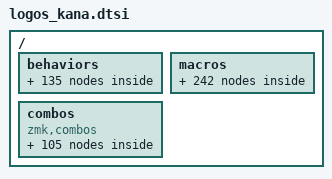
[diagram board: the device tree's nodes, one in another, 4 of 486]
// Generated by tools/generate_logos_kana_zmk.py. Do not edit manually.

#ifndef LOGOS_KANA_LAYER
#error "LOGOS_KANA_LAYER must be defined before including logos_kana.dtsi"
#endif
#ifndef LOGOS_KANA_TOTAL_POSITIONS
#error "LOGOS_KANA_TOTAL_POSITIONS must be defined before including logos_kana.dtsi"
#endif
#ifndef LOGOS_KANA_ROW_LENGTHS
#error "LOGOS_KANA_ROW_LENGTHS must be defined before including logos_kana.dtsi"
#endif
#ifndef LOGOS_KANA_TOGGLE_POSITION
#error "LOGOS_KANA_TOGGLE_POSITION must be defined before including logos_kana.dtsi"
#endif
#ifndef LOGOS_KANA_LAYER_BINDINGS
#error "LOGOS_KANA_LAYER_BINDINGS must be defined before including logos_kana.dtsi"
#endif
#ifndef LOGOS_KANA_POS_Q
#error "LOGOS_KANA_POS_Q must be defined before including logos_kana.dtsi"
#endif
#ifndef LOGOS_KANA_POS_W
#error "LOGOS_KANA_POS_W must be defined before including logos_kana.dtsi"
#endif
#ifndef LOGOS_KANA_POS_E
#error "LOGOS_KANA_POS_E must be defined before including logos_kana.dtsi"
#endif
#ifndef LOGOS_KANA_POS_R
#error "LOGOS_KANA_POS_R must be defined before including logos_kana.dtsi"
#endif
#ifndef LOGOS_KANA_POS_T
#error "LOGOS_KANA_POS_T must be defined before including logos_kana.dtsi"
#endif
#ifndef LOGOS_KANA_POS_Y
#error "LOGOS_KANA_POS_Y must be defined before including logos_kana.dtsi"
#endif
#ifndef LOGOS_KANA_POS_U
#error "LOGOS_KANA_POS_U must be defined before including logos_kana.dtsi"
#endif
#ifndef LOGOS_KANA_POS_I
#error "LOGOS_KANA_POS_I must be defined before including logos_kana.dtsi"
#endif
#ifndef LOGOS_KANA_POS_O
#error "LOGOS_KANA_POS_O must be defined before including logos_kana.dtsi"
#endif
#ifndef LOGOS_KANA_POS_P
#error "LOGOS_KANA_POS_P must be defined before including logos_kana.dtsi"
#endif
#ifndef LOGOS_KANA_POS_A
#error "LOGOS_KANA_POS_A must be defined before including logos_kana.dtsi"
#endif
#ifndef LOGOS_KANA_POS_S
#error "LOGOS_KANA_POS_S must be defined before including logos_kana.dtsi"
#endif
#ifndef LOGOS_KANA_POS_D
#error "LOGOS_KANA_POS_D must be defined before including logos_kana.dtsi"
#endif
#ifndef LOGOS_KANA_POS_F
#error "LOGOS_KANA_POS_F must be defined before including logos_kana.dtsi"
#endif
#ifndef LOGOS_KANA_POS_G
#error "LOGOS_KANA_POS_G must be defined before including logos_kana.dtsi"
#endif
#ifndef LOGOS_KANA_POS_H
#error "LOGOS_KANA_POS_H must be defined before including logos_kana.dtsi"
#endif
#ifndef LOGOS_KANA_POS_J
#error "LOGOS_KANA_POS_J must be defined before including logos_kana.dtsi"
#endif
#ifndef LOGOS_KANA_POS_K
#error "LOGOS_KANA_POS_K must be defined before including logos_kana.dtsi"
#endif
#ifndef LOGOS_KANA_POS_L
#error "LOGOS_KANA_POS_L must be defined before including logos_kana.dtsi"
#endif
#ifndef LOGOS_KANA_POS_SEMI
#error "LOGOS_KANA_POS_SEMI must be defined before including logos_kana.dtsi"
#endif
#ifndef LOGOS_KANA_POS_Z
#error "LOGOS_KANA_POS_Z must be defined before including logos_kana.dtsi"
#endif
#ifndef LOGOS_KANA_POS_X
#error "LOGOS_KANA_POS_X must be defined before including logos_kana.dtsi"
#endif
#ifndef LOGOS_KANA_POS_C
#error "LOGOS_KANA_POS_C must be defined before including logos_kana.dtsi"
#endif
#ifndef LOGOS_KANA_POS_V
#error "LOGOS_KANA_POS_V must be defined before including logos_kana.dtsi"
#endif
#ifndef LOGOS_KANA_POS_B
#error "LOGOS_KANA_POS_B must be defined before including logos_kana.dtsi"
#endif
#ifndef LOGOS_KANA_POS_N
#error "LOGOS_KANA_POS_N must be defined before including logos_kana.dtsi"
#endif
#ifndef LOGOS_KANA_POS_M
#error "LOGOS_KANA_POS_M must be defined before including logos_kana.dtsi"
#endif
#ifndef LOGOS_KANA_POS_COMMA
#error "LOGOS_KANA_POS_COMMA must be defined before including logos_kana.dtsi"
#endif
#ifndef LOGOS_KANA_POS_DOT
#error "LOGOS_KANA_POS_DOT must be defined before including logos_kana.dtsi"
#endif
#ifndef LOGOS_KANA_POS_SLASH
#error "LOGOS_KANA_POS_SLASH must be defined before including logos_kana.dtsi"
#endif
#ifndef LOGOS_KANA_FALLBACK_Q
#error "LOGOS_KANA_FALLBACK_Q must be defined before including logos_kana.dtsi"
#endif
#ifndef LOGOS_KANA_FALLBACK_W
#error "LOGOS_KANA_FALLBACK_W must be defined before including logos_kana.dtsi"
#endif
#ifndef LOGOS_KANA_FALLBACK_E
#error "LOGOS_KANA_FALLBACK_E must be defined before including logos_kana.dtsi"
#endif
#ifndef LOGOS_KANA_FALLBACK_R
#error "LOGOS_KANA_FALLBACK_R must be defined before including logos_kana.dtsi"
#endif
#ifndef LOGOS_KANA_FALLBACK_T
#error "LOGOS_KANA_FALLBACK_T must be defined before including logos_kana.dtsi"
#endif
#ifndef LOGOS_KANA_FALLBACK_Y
#error "LOGOS_KANA_FALLBACK_Y must be defined before including logos_kana.dtsi"
#endif
#ifndef LOGOS_KANA_FALLBACK_U
#error "LOGOS_KANA_FALLBACK_U must be defined before including logos_kana.dtsi"
#endif
#ifndef LOGOS_KANA_FALLBACK_I
#error "LOGOS_KANA_FALLBACK_I must be defined before including logos_kana.dtsi"
#endif
#ifndef LOGOS_KANA_FALLBACK_O
#error "LOGOS_KANA_FALLBACK_O must be defined before including logos_kana.dtsi"
#endif
#ifndef LOGOS_KANA_FALLBACK_P
#error "LOGOS_KANA_FALLBACK_P must be defined before including logos_kana.dtsi"
#endif
#ifndef LOGOS_KANA_FALLBACK_A
#error "LOGOS_KANA_FALLBACK_A must be defined before including logos_kana.dtsi"
#endif
#ifndef LOGOS_KANA_FALLBACK_S
#error "LOGOS_KANA_FALLBACK_S must be defined before including logos_kana.dtsi"
#endif
#ifndef LOGOS_KANA_FALLBACK_D
#error "LOGOS_KANA_FALLBACK_D must be defined before including logos_kana.dtsi"
#endif
#ifndef LOGOS_KANA_FALLBACK_F
#error "LOGOS_KANA_FALLBACK_F must be defined before including logos_kana.dtsi"
#endif
#ifndef LOGOS_KANA_FALLBACK_G
#error "LOGOS_KANA_FALLBACK_G must be defined before including logos_kana.dtsi"
#endif
#ifndef LOGOS_KANA_FALLBACK_H
#error "LOGOS_KANA_FALLBACK_H must be defined before including logos_kana.dtsi"
#endif
#ifndef LOGOS_KANA_FALLBACK_J
#error "LOGOS_KANA_FALLBACK_J must be defined before including logos_kana.dtsi"
#endif
#ifndef LOGOS_KANA_FALLBACK_K
#error "LOGOS_KANA_FALLBACK_K must be defined before including logos_kana.dtsi"
#endif
#ifndef LOGOS_KANA_FALLBACK_L
#error "LOGOS_KANA_FALLBACK_L must be defined before including logos_kana.dtsi"
#endif
#ifndef LOGOS_KANA_FALLBACK_SEMI
#error "LOGOS_KANA_FALLBACK_SEMI must be defined before including logos_kana.dtsi"
#endif
#ifndef LOGOS_KANA_FALLBACK_Z
#error "LOGOS_KANA_FALLBACK_Z must be defined before including logos_kana.dtsi"
#endif
#ifndef LOGOS_KANA_FALLBACK_X
#error "LOGOS_KANA_FALLBACK_X must be defined before including logos_kana.dtsi"
#endif
#ifndef LOGOS_KANA_FALLBACK_C
#error "LOGOS_KANA_FALLBACK_C must be defined before including logos_kana.dtsi"
#endif
#ifndef LOGOS_KANA_FALLBACK_V
#error "LOGOS_KANA_FALLBACK_V must be defined before including logos_kana.dtsi"
#endif
#ifndef LOGOS_KANA_FALLBACK_B
#error "LOGOS_KANA_FALLBACK_B must be defined before including logos_kana.dtsi"
#endif
#ifndef LOGOS_KANA_FALLBACK_N
#error "LOGOS_KANA_FALLBACK_N must be defined before including logos_kana.dtsi"
#endif
#ifndef LOGOS_KANA_FALLBACK_M
#error "LOGOS_KANA_FALLBACK_M must be defined before including logos_kana.dtsi"
#endif
#ifndef LOGOS_KANA_FALLBACK_COMMA
#error "LOGOS_KANA_FALLBACK_COMMA must be defined before including logos_kana.dtsi"
#endif
#ifndef LOGOS_KANA_FALLBACK_DOT
#error "LOGOS_KANA_FALLBACK_DOT must be defined before including logos_kana.dtsi"
#endif
#ifndef LOGOS_KANA_FALLBACK_SLASH
#error "LOGOS_KANA_FALLBACK_SLASH must be defined before including logos_kana.dtsi"
#endif

#ifndef LOGOS_KANA_COMBO_TIMEOUT_MS
#define LOGOS_KANA_COMBO_TIMEOUT_MS 60
#endif

#ifndef LOGOS_KANA_MACRO_WAIT_MS
#define LOGOS_KANA_MACRO_WAIT_MS 40
#endif

#ifndef LOGOS_KANA_MACRO_TAP_MS
#define LOGOS_KANA_MACRO_TAP_MS 40
#endif

#ifndef LOGOS_KANA_MODS
#define LOGOS_KANA_MODS (MOD_LCTL|MOD_RCTL|MOD_LSFT|MOD_RSFT|MOD_LALT|MOD_RALT|MOD_LGUI|MOD_RGUI)
#endif

#ifndef LOGOS_KANA_ON_BINDINGS
#define LOGOS_KANA_ON_BINDINGS <&tog LOGOS_KANA_LAYER>
#endif

#ifndef LOGOS_KANA_OFF_BINDINGS
#define LOGOS_KANA_OFF_BINDINGS <&tog LOGOS_KANA_LAYER>
#endif

#define LOGOS_KANA_LAYER_NODE \
        logos_kana_layer { \
            display-name = "Logos Kana"; \
            bindings = < \
LOGOS_KANA_LAYER_BINDINGS \
            >; \
        };

/ {
    behaviors {
        logos_kana_se_key: logos_kana_se_key {
            compatible = "zmk,behavior-mod-morph";
            #binding-cells = <0>;
            bindings = <&logos_kana_se>, <&kp LOGOS_KANA_FALLBACK_Q>;
            mods = <LOGOS_KANA_MODS>;
            keep-mods = <LOGOS_KANA_MODS>;
        };

        logos_kana_sa_key: logos_kana_sa_key {
            compatible = "zmk,behavior-mod-morph";
            #binding-cells = <0>;
            bindings = <&logos_kana_sa>, <&kp LOGOS_KANA_FALLBACK_W>;
            mods = <LOGOS_KANA_MODS>;
            keep-mods = <LOGOS_KANA_MODS>;
        };

        logos_kana_ha_key: logos_kana_ha_key {
            compatible = "zmk,behavior-mod-morph";
            #binding-cells = <0>;
            bindings = <&logos_kana_ha>, <&kp LOGOS_KANA_FALLBACK_E>;
            mods = <LOGOS_KANA_MODS>;
            keep-mods = <LOGOS_KANA_MODS>;
        };

        logos_kana_te_key: logos_kana_te_key {
            compatible = "zmk,behavior-mod-morph";
            #binding-cells = <0>;
            bindings = <&logos_kana_te>, <&kp LOGOS_KANA_FALLBACK_R>;
            mods = <LOGOS_KANA_MODS>;
            keep-mods = <LOGOS_KANA_MODS>;
        };

        logos_kana_wo_key: logos_kana_wo_key {
            compatible = "zmk,behavior-mod-morph";
            #binding-cells = <0>;
            bindings = <&logos_kana_wo>, <&kp LOGOS_KANA_FALLBACK_T>;
            mods = <LOGOS_KANA_MODS>;
            keep-mods = <LOGOS_KANA_MODS>;
        };

        logos_kana_ti_key: logos_kana_ti_key {
            compatible = "zmk,behavior-mod-morph";
            #binding-cells = <0>;
            bindings = <&logos_kana_ti>, <&kp LOGOS_KANA_FALLBACK_Y>;
            mods = <LOGOS_KANA_MODS>;
            keep-mods = <LOGOS_KANA_MODS>;
        };

        logos_kana_tu_key: logos_kana_tu_key {
            compatible = "zmk,behavior-mod-morph";
            #binding-cells = <0>;
            bindings = <&logos_kana_tu>, <&kp LOGOS_KANA_FALLBACK_U>;
            mods = <LOGOS_KANA_MODS>;
            keep-mods = <LOGOS_KANA_MODS>;
        };

        logos_kana_ku_key: logos_kana_ku_key {
            compatible = "zmk,behavior-mod-morph";
            #binding-cells = <0>;
            bindings = <&logos_kana_ku>, <&kp LOGOS_KANA_FALLBACK_I>;
            mods = <LOGOS_KANA_MODS>;
            keep-mods = <LOGOS_KANA_MODS>;
        };

        logos_kana_xtu_key: logos_kana_xtu_key {
            compatible = "zmk,behavior-mod-morph";
            #binding-cells = <0>;
            bindings = <&logos_kana_xtu>, <&kp LOGOS_KANA_FALLBACK_O>;
            mods = <LOGOS_KANA_MODS>;
            keep-mods = <LOGOS_KANA_MODS>;
        };

        logos_kana_hi_key: logos_kana_hi_key {
            compatible = "zmk,behavior-mod-morph";
            #binding-cells = <0>;
            bindings = <&logos_kana_hi>, <&kp LOGOS_KANA_FALLBACK_P>;
            mods = <LOGOS_KANA_MODS>;
            keep-mods = <LOGOS_KANA_MODS>;
        };

        logos_kana_ka_key: logos_kana_ka_key {
            compatible = "zmk,behavior-mod-morph";
            #binding-cells = <0>;
            bindings = <&logos_kana_ka>, <&kp LOGOS_KANA_FALLBACK_A>;
            mods = <LOGOS_KANA_MODS>;
            keep-mods = <LOGOS_KANA_MODS>;
        };

        logos_kana_to_key: logos_kana_to_key {
            compatible = "zmk,behavior-mod-morph";
            #binding-cells = <0>;
            bindings = <&logos_kana_to>, <&kp LOGOS_KANA_FALLBACK_S>;
            mods = <LOGOS_KANA_MODS>;
            keep-mods = <LOGOS_KANA_MODS>;
        };

        logos_kana_ta_key: logos_kana_ta_key {
            compatible = "zmk,behavior-mod-morph";
            #binding-cells = <0>;
            bindings = <&logos_kana_ta>, <&kp LOGOS_KANA_FALLBACK_D>;
            mods = <LOGOS_KANA_MODS>;
            keep-mods = <LOGOS_KANA_MODS>;
        };

        logos_kana_no_key: logos_kana_no_key {
            compatible = "zmk,behavior-mod-morph";
            #binding-cells = <0>;
            bindings = <&logos_kana_no>, <&kp LOGOS_KANA_FALLBACK_F>;
            mods = <LOGOS_KANA_MODS>;
            keep-mods = <LOGOS_KANA_MODS>;
        };

        logos_kana_ni_key: logos_kana_ni_key {
            compatible = "zmk,behavior-mod-morph";
            #binding-cells = <0>;
            bindings = <&logos_kana_ni>, <&kp LOGOS_KANA_FALLBACK_G>;
            mods = <LOGOS_KANA_MODS>;
            keep-mods = <LOGOS_KANA_MODS>;
        };

        logos_kana_comma_key: logos_kana_comma_key {
            compatible = "zmk,behavior-mod-morph";
            #binding-cells = <0>;
            bindings = <&logos_kana_comma>, <&kp LOGOS_KANA_FALLBACK_H>;
            mods = <LOGOS_KANA_MODS>;
            keep-mods = <LOGOS_KANA_MODS>;
        };

        logos_kana_nn_key: logos_kana_nn_key {
            compatible = "zmk,behavior-mod-morph";
            #binding-cells = <0>;
            bindings = <&logos_kana_nn>, <&kp LOGOS_KANA_FALLBACK_J>;
            mods = <LOGOS_KANA_MODS>;
            keep-mods = <LOGOS_KANA_MODS>;
        };

        logos_kana_i_key: logos_kana_i_key {
            compatible = "zmk,behavior-mod-morph";
            #binding-cells = <0>;
            bindings = <&logos_kana_i>, <&kp LOGOS_KANA_FALLBACK_K>;
            mods = <LOGOS_KANA_MODS>;
            keep-mods = <LOGOS_KANA_MODS>;
        };

        logos_kana_u_key: logos_kana_u_key {
            compatible = "zmk,behavior-mod-morph";
            #binding-cells = <0>;
            bindings = <&logos_kana_u>, <&kp LOGOS_KANA_FALLBACK_L>;
            mods = <LOGOS_KANA_MODS>;
            keep-mods = <LOGOS_KANA_MODS>;
        };

        logos_kana_si_key: logos_kana_si_key {
            compatible = "zmk,behavior-mod-morph";
            #binding-cells = <0>;
            bindings = <&logos_kana_si>, <&kp LOGOS_KANA_FALLBACK_SEMI>;
            mods = <LOGOS_KANA_MODS>;
            keep-mods = <LOGOS_KANA_MODS>;
        };

        logos_kana_yo_key: logos_kana_yo_key {
            compatible = "zmk,behavior-mod-morph";
            #binding-cells = <0>;
            bindings = <&logos_kana_yo>, <&kp LOGOS_KANA_FALLBACK_Z>;
            mods = <LOGOS_KANA_MODS>;
            keep-mods = <LOGOS_KANA_MODS>;
        };

        logos_kana_da_key: logos_kana_da_key {
            compatible = "zmk,behavior-mod-morph";
            #binding-cells = <0>;
            bindings = <&logos_kana_da>, <&kp LOGOS_KANA_FALLBACK_X>;
            mods = <LOGOS_KANA_MODS>;
            keep-mods = <LOGOS_KANA_MODS>;
        };

        logos_kana_do_key: logos_kana_do_key {
            compatible = "zmk,behavior-mod-morph";
            #binding-cells = <0>;
            bindings = <&logos_kana_do>, <&kp LOGOS_KANA_FALLBACK_C>;
            mods = <LOGOS_KANA_MODS>;
            keep-mods = <LOGOS_KANA_MODS>;
        };

        logos_kana_ga_key: logos_kana_ga_key {
            compatible = "zmk,behavior-mod-morph";
            #binding-cells = <0>;
            bindings = <&logos_kana_ga>, <&kp LOGOS_KANA_FALLBACK_V>;
            mods = <LOGOS_KANA_MODS>;
            keep-mods = <LOGOS_KANA_MODS>;
        };

        logos_kana_ra_key: logos_kana_ra_key {
            compatible = "zmk,behavior-mod-morph";
            #binding-cells = <0>;
            bindings = <&logos_kana_ra>, <&kp LOGOS_KANA_FALLBACK_B>;
            mods = <LOGOS_KANA_MODS>;
            keep-mods = <LOGOS_KANA_MODS>;
        };

        logos_kana_wa_key: logos_kana_wa_key {
            compatible = "zmk,behavior-mod-morph";
            #binding-cells = <0>;
            bindings = <&logos_kana_wa>, <&kp LOGOS_KANA_FALLBACK_N>;
            mods = <LOGOS_KANA_MODS>;
            keep-mods = <LOGOS_KANA_MODS>;
        };

        logos_kana_ru_key: logos_kana_ru_key {
            compatible = "zmk,behavior-mod-morph";
            #binding-cells = <0>;
            bindings = <&logos_kana_ru>, <&kp LOGOS_KANA_FALLBACK_M>;
            mods = <LOGOS_KANA_MODS>;
            keep-mods = <LOGOS_KANA_MODS>;
        };

        logos_kana_long_key: logos_kana_long_key {
            compatible = "zmk,behavior-mod-morph";
            #binding-cells = <0>;
            bindings = <&logos_kana_long>, <&kp LOGOS_KANA_FALLBACK_COMMA>;
            mods = <LOGOS_KANA_MODS>;
            keep-mods = <LOGOS_KANA_MODS>;
        };

        logos_kana_re_key: logos_kana_re_key {
            compatible = "zmk,behavior-mod-morph";
            #binding-cells = <0>;
            bindings = <&logos_kana_re>, <&kp LOGOS_KANA_FALLBACK_DOT>;
            mods = <LOGOS_KANA_MODS>;
            keep-mods = <LOGOS_KANA_MODS>;
        };

        logos_kana_e_key: logos_kana_e_key {
            compatible = "zmk,behavior-mod-morph";
            #binding-cells = <0>;
            bindings = <&logos_kana_e>, <&kp LOGOS_KANA_FALLBACK_SLASH>;
            mods = <LOGOS_KANA_MODS>;
            keep-mods = <LOGOS_KANA_MODS>;
        };

        logos_kana_di_combo: logos_kana_di_combo {
            compatible = "zmk,behavior-mod-morph";
            #binding-cells = <0>;
            bindings = <&logos_kana_di>, <&logos_kana_di_pass>;
            mods = <LOGOS_KANA_MODS>;
            keep-mods = <LOGOS_KANA_MODS>;
        };

        logos_kana_ge_combo: logos_kana_ge_combo {
            compatible = "zmk,behavior-mod-morph";
            #binding-cells = <0>;
            bindings = <&logos_kana_ge>, <&logos_kana_ge_pass>;
            mods = <LOGOS_KANA_MODS>;
            keep-mods = <LOGOS_KANA_MODS>;
        };

        logos_kana_ho_combo: logos_kana_ho_combo {
            compatible = "zmk,behavior-mod-morph";
            #binding-cells = <0>;
            bindings = <&logos_kana_ho>, <&logos_kana_ho_pass>;
            mods = <LOGOS_KANA_MODS>;
            keep-mods = <LOGOS_KANA_MODS>;
        };

        logos_kana_gi_combo: logos_kana_gi_combo {
            compatible = "zmk,behavior-mod-morph";
            #binding-cells = <0>;
            bindings = <&logos_kana_gi>, <&logos_kana_gi_pass>;
            mods = <LOGOS_KANA_MODS>;
            keep-mods = <LOGOS_KANA_MODS>;
        };

        logos_kana_ze_combo: logos_kana_ze_combo {
            compatible = "zmk,behavior-mod-morph";
            #binding-cells = <0>;
            bindings = <&logos_kana_ze>, <&logos_kana_ze_pass>;
            mods = <LOGOS_KANA_MODS>;
            keep-mods = <LOGOS_KANA_MODS>;
        };

        logos_kana_du_combo: logos_kana_du_combo {
            compatible = "zmk,behavior-mod-morph";
            #binding-cells = <0>;
            bindings = <&logos_kana_du>, <&logos_kana_du_pass>;
            mods = <LOGOS_KANA_MODS>;
            keep-mods = <LOGOS_KANA_MODS>;
        };

        logos_kana_yu_combo: logos_kana_yu_combo {
            compatible = "zmk,behavior-mod-morph";
            #binding-cells = <0>;
            bindings = <&logos_kana_yu>, <&logos_kana_yu_pass>;
            mods = <LOGOS_KANA_MODS>;
            keep-mods = <LOGOS_KANA_MODS>;
        };

        logos_kana_hu_combo: logos_kana_hu_combo {
            compatible = "zmk,behavior-mod-morph";
            #binding-cells = <0>;
            bindings = <&logos_kana_hu>, <&logos_kana_hu_pass>;
            mods = <LOGOS_KANA_MODS>;
            keep-mods = <LOGOS_KANA_MODS>;
        };

        logos_kana_bi_combo: logos_kana_bi_combo {
            compatible = "zmk,behavior-mod-morph";
            #binding-cells = <0>;
            bindings = <&logos_kana_bi>, <&logos_kana_bi_pass>;
            mods = <LOGOS_KANA_MODS>;
            keep-mods = <LOGOS_KANA_MODS>;
        };

        logos_kana_vu_combo: logos_kana_vu_combo {
            compatible = "zmk,behavior-mod-morph";
            #binding-cells = <0>;
            bindings = <&logos_kana_vu>, <&logos_kana_vu_pass>;
            mods = <LOGOS_KANA_MODS>;
            keep-mods = <LOGOS_KANA_MODS>;
        };

        logos_kana_ke_combo: logos_kana_ke_combo {
            compatible = "zmk,behavior-mod-morph";
            #binding-cells = <0>;
            bindings = <&logos_kana_ke>, <&logos_kana_ke_pass>;
            mods = <LOGOS_KANA_MODS>;
            keep-mods = <LOGOS_KANA_MODS>;
        };

        logos_kana_na_combo: logos_kana_na_combo {
            compatible = "zmk,behavior-mod-morph";
            #binding-cells = <0>;
            bindings = <&logos_kana_na>, <&logos_kana_na_pass>;
            mods = <LOGOS_KANA_MODS>;
            keep-mods = <LOGOS_KANA_MODS>;
        };

        logos_kana_ko_combo: logos_kana_ko_combo {
            compatible = "zmk,behavior-mod-morph";
            #binding-cells = <0>;
            bindings = <&logos_kana_ko>, <&logos_kana_ko_pass>;
            mods = <LOGOS_KANA_MODS>;
            keep-mods = <LOGOS_KANA_MODS>;
        };

        logos_kana_period_combo: logos_kana_period_combo {
            compatible = "zmk,behavior-mod-morph";
            #binding-cells = <0>;
            bindings = <&logos_kana_period>, <&logos_kana_period_pass>;
            mods = <LOGOS_KANA_MODS>;
            keep-mods = <LOGOS_KANA_MODS>;
        };

        logos_kana_zi_combo: logos_kana_zi_combo {
            compatible = "zmk,behavior-mod-morph";
            #binding-cells = <0>;
            bindings = <&logos_kana_zi>, <&logos_kana_zi_pass>;
            mods = <LOGOS_KANA_MODS>;
            keep-mods = <LOGOS_KANA_MODS>;
        };

        logos_kana_so_combo: logos_kana_so_combo {
            compatible = "zmk,behavior-mod-morph";
            #binding-cells = <0>;
            bindings = <&logos_kana_so>, <&logos_kana_so_pass>;
            mods = <LOGOS_KANA_MODS>;
            keep-mods = <LOGOS_KANA_MODS>;
        };

        logos_kana_o_combo: logos_kana_o_combo {
            compatible = "zmk,behavior-mod-morph";
            #binding-cells = <0>;
            bindings = <&logos_kana_o>, <&logos_kana_o_pass>;
            mods = <LOGOS_KANA_MODS>;
            keep-mods = <LOGOS_KANA_MODS>;
        };

        logos_kana_a_combo: logos_kana_a_combo {
            compatible = "zmk,behavior-mod-morph";
            #binding-cells = <0>;
            bindings = <&logos_kana_a>, <&logos_kana_a_pass>;
            mods = <LOGOS_KANA_MODS>;
            keep-mods = <LOGOS_KANA_MODS>;
        };

        logos_kana_pi_combo: logos_kana_pi_combo {
            compatible = "zmk,behavior-mod-morph";
            #binding-cells = <0>;
            bindings = <&logos_kana_pi>, <&logos_kana_pi_pass>;
            mods = <LOGOS_KANA_MODS>;
            keep-mods = <LOGOS_KANA_MODS>;
        };

        logos_kana_po_combo: logos_kana_po_combo {
            compatible = "zmk,behavior-mod-morph";
            #binding-cells = <0>;
            bindings = <&logos_kana_po>, <&logos_kana_po_pass>;
            mods = <LOGOS_KANA_MODS>;
            keep-mods = <LOGOS_KANA_MODS>;
        };

        logos_kana_ne_combo: logos_kana_ne_combo {
            compatible = "zmk,behavior-mod-morph";
            #binding-cells = <0>;
            bindings = <&logos_kana_ne>, <&logos_kana_ne_pass>;
            mods = <LOGOS_KANA_MODS>;
            keep-mods = <LOGOS_KANA_MODS>;
        };

        logos_kana_ba_combo: logos_kana_ba_combo {
            compatible = "zmk,behavior-mod-morph";
            #binding-cells = <0>;
            bindings = <&logos_kana_ba>, <&logos_kana_ba_pass>;
            mods = <LOGOS_KANA_MODS>;
            keep-mods = <LOGOS_KANA_MODS>;
        };

        logos_kana_pa_combo: logos_kana_pa_combo {
            compatible = "zmk,behavior-mod-morph";
            #binding-cells = <0>;
            bindings = <&logos_kana_pa>, <&logos_kana_pa_pass>;
            mods = <LOGOS_KANA_MODS>;
            keep-mods = <LOGOS_KANA_MODS>;
        };

        logos_kana_nu_combo: logos_kana_nu_combo {
            compatible = "zmk,behavior-mod-morph";
            #binding-cells = <0>;
            bindings = <&logos_kana_nu>, <&logos_kana_nu_pass>;
            mods = <LOGOS_KANA_MODS>;
            keep-mods = <LOGOS_KANA_MODS>;
        };

        logos_kana_mi_combo: logos_kana_mi_combo {
            compatible = "zmk,behavior-mod-morph";
            #binding-cells = <0>;
            bindings = <&logos_kana_mi>, <&logos_kana_mi_pass>;
            mods = <LOGOS_KANA_MODS>;
            keep-mods = <LOGOS_KANA_MODS>;
        };

        logos_kana_gu_combo: logos_kana_gu_combo {
            compatible = "zmk,behavior-mod-morph";
            #binding-cells = <0>;
            bindings = <&logos_kana_gu>, <&logos_kana_gu_pass>;
            mods = <LOGOS_KANA_MODS>;
            keep-mods = <LOGOS_KANA_MODS>;
        };

        logos_kana_dhi_combo: logos_kana_dhi_combo {
            compatible = "zmk,behavior-mod-morph";
            #binding-cells = <0>;
            bindings = <&logos_kana_dhi>, <&logos_kana_dhi_pass>;
            mods = <LOGOS_KANA_MODS>;
            keep-mods = <LOGOS_KANA_MODS>;
        };

        logos_kana_pu_combo: logos_kana_pu_combo {
            compatible = "zmk,behavior-mod-morph";
            #binding-cells = <0>;
            bindings = <&logos_kana_pu>, <&logos_kana_pu_pass>;
            mods = <LOGOS_KANA_MODS>;
            keep-mods = <LOGOS_KANA_MODS>;
        };

        logos_kana_xa_combo: logos_kana_xa_combo {
            compatible = "zmk,behavior-mod-morph";
            #binding-cells = <0>;
            bindings = <&logos_kana_xa>, <&logos_kana_xa_pass>;
            mods = <LOGOS_KANA_MODS>;
            keep-mods = <LOGOS_KANA_MODS>;
        };

        logos_kana_me_combo: logos_kana_me_combo {
            compatible = "zmk,behavior-mod-morph";
            #binding-cells = <0>;
            bindings = <&logos_kana_me>, <&logos_kana_me_pass>;
            mods = <LOGOS_KANA_MODS>;
            keep-mods = <LOGOS_KANA_MODS>;
        };

        logos_kana_bu_combo: logos_kana_bu_combo {
            compatible = "zmk,behavior-mod-morph";
            #binding-cells = <0>;
            bindings = <&logos_kana_bu>, <&logos_kana_bu_pass>;
            mods = <LOGOS_KANA_MODS>;
            keep-mods = <LOGOS_KANA_MODS>;
        };

        logos_kana_za_combo: logos_kana_za_combo {
            compatible = "zmk,behavior-mod-morph";
            #binding-cells = <0>;
            bindings = <&logos_kana_za>, <&logos_kana_za_pass>;
            mods = <LOGOS_KANA_MODS>;
            keep-mods = <LOGOS_KANA_MODS>;
        };

        logos_kana_xi_combo: logos_kana_xi_combo {
            compatible = "zmk,behavior-mod-morph";
            #binding-cells = <0>;
            bindings = <&logos_kana_xi>, <&logos_kana_xi_pass>;
            mods = <LOGOS_KANA_MODS>;
            keep-mods = <LOGOS_KANA_MODS>;
        };

        logos_kana_xu_combo: logos_kana_xu_combo {
            compatible = "zmk,behavior-mod-morph";
            #binding-cells = <0>;
            bindings = <&logos_kana_xu>, <&logos_kana_xu_pass>;
            mods = <LOGOS_KANA_MODS>;
            keep-mods = <LOGOS_KANA_MODS>;
        };

        logos_kana_zo_combo: logos_kana_zo_combo {
            compatible = "zmk,behavior-mod-morph";
            #binding-cells = <0>;
            bindings = <&logos_kana_zo>, <&logos_kana_zo_pass>;
            mods = <LOGOS_KANA_MODS>;
            keep-mods = <LOGOS_KANA_MODS>;
        };

        logos_kana_go_combo: logos_kana_go_combo {
            compatible = "zmk,behavior-mod-morph";
            #binding-cells = <0>;
            bindings = <&logos_kana_go>, <&logos_kana_go_pass>;
            mods = <LOGOS_KANA_MODS>;
            keep-mods = <LOGOS_KANA_MODS>;
        };

        logos_kana_be_combo: logos_kana_be_combo {
            compatible = "zmk,behavior-mod-morph";
            #binding-cells = <0>;
            bindings = <&logos_kana_be>, <&logos_kana_be_pass>;
            mods = <LOGOS_KANA_MODS>;
            keep-mods = <LOGOS_KANA_MODS>;
        };

        logos_kana_xe_combo: logos_kana_xe_combo {
            compatible = "zmk,behavior-mod-morph";
            #binding-cells = <0>;
            bindings = <&logos_kana_xe>, <&logos_kana_xe_pass>;
            mods = <LOGOS_KANA_MODS>;
            keep-mods = <LOGOS_KANA_MODS>;
        };

        logos_kana_ki_combo: logos_kana_ki_combo {
            compatible = "zmk,behavior-mod-morph";
            #binding-cells = <0>;
            bindings = <&logos_kana_ki>, <&logos_kana_ki_pass>;
            mods = <LOGOS_KANA_MODS>;
            keep-mods = <LOGOS_KANA_MODS>;
        };

        logos_kana_ri_combo: logos_kana_ri_combo {
            compatible = "zmk,behavior-mod-morph";
            #binding-cells = <0>;
            bindings = <&logos_kana_ri>, <&logos_kana_ri_pass>;
            mods = <LOGOS_KANA_MODS>;
            keep-mods = <LOGOS_KANA_MODS>;
        };

        logos_kana_su_combo: logos_kana_su_combo {
            compatible = "zmk,behavior-mod-morph";
            #binding-cells = <0>;
            bindings = <&logos_kana_su>, <&logos_kana_su_pass>;
            mods = <LOGOS_KANA_MODS>;
            keep-mods = <LOGOS_KANA_MODS>;
        };

        logos_kana_de_combo: logos_kana_de_combo {
            compatible = "zmk,behavior-mod-morph";
            #binding-cells = <0>;
            bindings = <&logos_kana_de>, <&logos_kana_de_pass>;
            mods = <LOGOS_KANA_MODS>;
            keep-mods = <LOGOS_KANA_MODS>;
        };

        logos_kana_ya_combo: logos_kana_ya_combo {
            compatible = "zmk,behavior-mod-morph";
            #binding-cells = <0>;
            bindings = <&logos_kana_ya>, <&logos_kana_ya_pass>;
            mods = <LOGOS_KANA_MODS>;
            keep-mods = <LOGOS_KANA_MODS>;
        };

        logos_kana_ro_combo: logos_kana_ro_combo {
            compatible = "zmk,behavior-mod-morph";
            #binding-cells = <0>;
            bindings = <&logos_kana_ro>, <&logos_kana_ro_pass>;
            mods = <LOGOS_KANA_MODS>;
            keep-mods = <LOGOS_KANA_MODS>;
        };

        logos_kana_ma_combo: logos_kana_ma_combo {
            compatible = "zmk,behavior-mod-morph";
            #binding-cells = <0>;
            bindings = <&logos_kana_ma>, <&logos_kana_ma_pass>;
            mods = <LOGOS_KANA_MODS>;
            keep-mods = <LOGOS_KANA_MODS>;
        };

        logos_kana_mo_combo: logos_kana_mo_combo {
            compatible = "zmk,behavior-mod-morph";
            #binding-cells = <0>;
            bindings = <&logos_kana_mo>, <&logos_kana_mo_pass>;
            mods = <LOGOS_KANA_MODS>;
            keep-mods = <LOGOS_KANA_MODS>;
        };

        logos_kana_xo_combo: logos_kana_xo_combo {
            compatible = "zmk,behavior-mod-morph";
            #binding-cells = <0>;
            bindings = <&logos_kana_xo>, <&logos_kana_xo_pass>;
            mods = <LOGOS_KANA_MODS>;
            keep-mods = <LOGOS_KANA_MODS>;
        };

        logos_kana_pe_combo: logos_kana_pe_combo {
            compatible = "zmk,behavior-mod-morph";
            #binding-cells = <0>;
            bindings = <&logos_kana_pe>, <&logos_kana_pe_pass>;
            mods = <LOGOS_KANA_MODS>;
            keep-mods = <LOGOS_KANA_MODS>;
        };

        logos_kana_bo_combo: logos_kana_bo_combo {
            compatible = "zmk,behavior-mod-morph";
            #binding-cells = <0>;
            bindings = <&logos_kana_bo>, <&logos_kana_bo_pass>;
            mods = <LOGOS_KANA_MODS>;
            keep-mods = <LOGOS_KANA_MODS>;
        };

        logos_kana_he_combo: logos_kana_he_combo {
            compatible = "zmk,behavior-mod-morph";
            #binding-cells = <0>;
            bindings = <&logos_kana_he>, <&logos_kana_he_pass>;
            mods = <LOGOS_KANA_MODS>;
            keep-mods = <LOGOS_KANA_MODS>;
        };

        logos_kana_xya_combo: logos_kana_xya_combo {
            compatible = "zmk,behavior-mod-morph";
            #binding-cells = <0>;
            bindings = <&logos_kana_xya>, <&logos_kana_xya_pass>;
            mods = <LOGOS_KANA_MODS>;
            keep-mods = <LOGOS_KANA_MODS>;
        };

        logos_kana_xyu_combo: logos_kana_xyu_combo {
            compatible = "zmk,behavior-mod-morph";
            #binding-cells = <0>;
            bindings = <&logos_kana_xyu>, <&logos_kana_xyu_pass>;
            mods = <LOGOS_KANA_MODS>;
            keep-mods = <LOGOS_KANA_MODS>;
        };

        logos_kana_mu_combo: logos_kana_mu_combo {
            compatible = "zmk,behavior-mod-morph";
            #binding-cells = <0>;
            bindings = <&logos_kana_mu>, <&logos_kana_mu_pass>;
            mods = <LOGOS_KANA_MODS>;
            keep-mods = <LOGOS_KANA_MODS>;
        };

        logos_kana_zu_combo: logos_kana_zu_combo {
            compatible = "zmk,behavior-mod-morph";
            #binding-cells = <0>;
            bindings = <&logos_kana_zu>, <&logos_kana_zu_pass>;
            mods = <LOGOS_KANA_MODS>;
            keep-mods = <LOGOS_KANA_MODS>;
        };

        logos_kana_thi_combo: logos_kana_thi_combo {
            compatible = "zmk,behavior-mod-morph";
            #binding-cells = <0>;
            bindings = <&logos_kana_thi>, <&logos_kana_thi_pass>;
            mods = <LOGOS_KANA_MODS>;
            keep-mods = <LOGOS_KANA_MODS>;
        };

        logos_kana_xyo_combo: logos_kana_xyo_combo {
            compatible = "zmk,behavior-mod-morph";
            #binding-cells = <0>;
            bindings = <&logos_kana_xyo>, <&logos_kana_xyo_pass>;
            mods = <LOGOS_KANA_MODS>;
            keep-mods = <LOGOS_KANA_MODS>;
        };

        logos_kana_sya_combo: logos_kana_sya_combo {
            compatible = "zmk,behavior-mod-morph";
            #binding-cells = <0>;
            bindings = <&logos_kana_sya>, <&logos_kana_sya_pass>;
            mods = <LOGOS_KANA_MODS>;
            keep-mods = <LOGOS_KANA_MODS>;
        };

        logos_kana_syu_combo: logos_kana_syu_combo {
            compatible = "zmk,behavior-mod-morph";
            #binding-cells = <0>;
            bindings = <&logos_kana_syu>, <&logos_kana_syu_pass>;
            mods = <LOGOS_KANA_MODS>;
            keep-mods = <LOGOS_KANA_MODS>;
        };

        logos_kana_syo_combo: logos_kana_syo_combo {
            compatible = "zmk,behavior-mod-morph";
            #binding-cells = <0>;
            bindings = <&logos_kana_syo>, <&logos_kana_syo_pass>;
            mods = <LOGOS_KANA_MODS>;
            keep-mods = <LOGOS_KANA_MODS>;
        };

        logos_kana_kya_combo: logos_kana_kya_combo {
            compatible = "zmk,behavior-mod-morph";
            #binding-cells = <0>;
            bindings = <&logos_kana_kya>, <&logos_kana_kya_pass>;
            mods = <LOGOS_KANA_MODS>;
            keep-mods = <LOGOS_KANA_MODS>;
        };

        logos_kana_kyu_combo: logos_kana_kyu_combo {
            compatible = "zmk,behavior-mod-morph";
            #binding-cells = <0>;
            bindings = <&logos_kana_kyu>, <&logos_kana_kyu_pass>;
            mods = <LOGOS_KANA_MODS>;
            keep-mods = <LOGOS_KANA_MODS>;
        };

        logos_kana_kyo_combo: logos_kana_kyo_combo {
            compatible = "zmk,behavior-mod-morph";
            #binding-cells = <0>;
            bindings = <&logos_kana_kyo>, <&logos_kana_kyo_pass>;
            mods = <LOGOS_KANA_MODS>;
            keep-mods = <LOGOS_KANA_MODS>;
        };

        logos_kana_tya_combo: logos_kana_tya_combo {
            compatible = "zmk,behavior-mod-morph";
            #binding-cells = <0>;
            bindings = <&logos_kana_tya>, <&logos_kana_tya_pass>;
            mods = <LOGOS_KANA_MODS>;
            keep-mods = <LOGOS_KANA_MODS>;
        };

        logos_kana_tyu_combo: logos_kana_tyu_combo {
            compatible = "zmk,behavior-mod-morph";
            #binding-cells = <0>;
            bindings = <&logos_kana_tyu>, <&logos_kana_tyu_pass>;
            mods = <LOGOS_KANA_MODS>;
            keep-mods = <LOGOS_KANA_MODS>;
        };

        logos_kana_tyo_combo: logos_kana_tyo_combo {
            compatible = "zmk,behavior-mod-morph";
            #binding-cells = <0>;
            bindings = <&logos_kana_tyo>, <&logos_kana_tyo_pass>;
            mods = <LOGOS_KANA_MODS>;
            keep-mods = <LOGOS_KANA_MODS>;
        };

        logos_kana_hya_combo: logos_kana_hya_combo {
            compatible = "zmk,behavior-mod-morph";
            #binding-cells = <0>;
            bindings = <&logos_kana_hya>, <&logos_kana_hya_pass>;
            mods = <LOGOS_KANA_MODS>;
            keep-mods = <LOGOS_KANA_MODS>;
        };

        logos_kana_hyu_combo: logos_kana_hyu_combo {
            compatible = "zmk,behavior-mod-morph";
            #binding-cells = <0>;
            bindings = <&logos_kana_hyu>, <&logos_kana_hyu_pass>;
            mods = <LOGOS_KANA_MODS>;
            keep-mods = <LOGOS_KANA_MODS>;
        };

        logos_kana_hyo_combo: logos_kana_hyo_combo {
            compatible = "zmk,behavior-mod-morph";
            #binding-cells = <0>;
            bindings = <&logos_kana_hyo>, <&logos_kana_hyo_pass>;
            mods = <LOGOS_KANA_MODS>;
            keep-mods = <LOGOS_KANA_MODS>;
        };

        logos_kana_ja_combo: logos_kana_ja_combo {
            compatible = "zmk,behavior-mod-morph";
            #binding-cells = <0>;
            bindings = <&logos_kana_ja>, <&logos_kana_ja_pass>;
            mods = <LOGOS_KANA_MODS>;
            keep-mods = <LOGOS_KANA_MODS>;
        };

        logos_kana_ju_combo: logos_kana_ju_combo {
            compatible = "zmk,behavior-mod-morph";
            #binding-cells = <0>;
            bindings = <&logos_kana_ju>, <&logos_kana_ju_pass>;
            mods = <LOGOS_KANA_MODS>;
            keep-mods = <LOGOS_KANA_MODS>;
        };

        logos_kana_jo_combo: logos_kana_jo_combo {
            compatible = "zmk,behavior-mod-morph";
            #binding-cells = <0>;
            bindings = <&logos_kana_jo>, <&logos_kana_jo_pass>;
            mods = <LOGOS_KANA_MODS>;
            keep-mods = <LOGOS_KANA_MODS>;
        };

        logos_kana_gya_combo: logos_kana_gya_combo {
            compatible = "zmk,behavior-mod-morph";
            #binding-cells = <0>;
            bindings = <&logos_kana_gya>, <&logos_kana_gya_pass>;
            mods = <LOGOS_KANA_MODS>;
            keep-mods = <LOGOS_KANA_MODS>;
        };

        logos_kana_gyu_combo: logos_kana_gyu_combo {
            compatible = "zmk,behavior-mod-morph";
            #binding-cells = <0>;
            bindings = <&logos_kana_gyu>, <&logos_kana_gyu_pass>;
            mods = <LOGOS_KANA_MODS>;
            keep-mods = <LOGOS_KANA_MODS>;
        };

        logos_kana_gyo_combo: logos_kana_gyo_combo {
            compatible = "zmk,behavior-mod-morph";
            #binding-cells = <0>;
            bindings = <&logos_kana_gyo>, <&logos_kana_gyo_pass>;
            mods = <LOGOS_KANA_MODS>;
            keep-mods = <LOGOS_KANA_MODS>;
        };

        logos_kana_nya_combo: logos_kana_nya_combo {
            compatible = "zmk,behavior-mod-morph";
            #binding-cells = <0>;
            bindings = <&logos_kana_nya>, <&logos_kana_nya_pass>;
            mods = <LOGOS_KANA_MODS>;
            keep-mods = <LOGOS_KANA_MODS>;
        };

        logos_kana_nyu_combo: logos_kana_nyu_combo {
            compatible = "zmk,behavior-mod-morph";
            #binding-cells = <0>;
            bindings = <&logos_kana_nyu>, <&logos_kana_nyu_pass>;
            mods = <LOGOS_KANA_MODS>;
            keep-mods = <LOGOS_KANA_MODS>;
        };

        logos_kana_nyo_combo: logos_kana_nyo_combo {
            compatible = "zmk,behavior-mod-morph";
            #binding-cells = <0>;
            bindings = <&logos_kana_nyo>, <&logos_kana_nyo_pass>;
            mods = <LOGOS_KANA_MODS>;
            keep-mods = <LOGOS_KANA_MODS>;
        };

        logos_kana_bya_combo: logos_kana_bya_combo {
            compatible = "zmk,behavior-mod-morph";
            #binding-cells = <0>;
            bindings = <&logos_kana_bya>, <&logos_kana_bya_pass>;
            mods = <LOGOS_KANA_MODS>;
            keep-mods = <LOGOS_KANA_MODS>;
        };

        logos_kana_byu_combo: logos_kana_byu_combo {
            compatible = "zmk,behavior-mod-morph";
            #binding-cells = <0>;
            bindings = <&logos_kana_byu>, <&logos_kana_byu_pass>;
            mods = <LOGOS_KANA_MODS>;
            keep-mods = <LOGOS_KANA_MODS>;
        };

        logos_kana_byo_combo: logos_kana_byo_combo {
            compatible = "zmk,behavior-mod-morph";
            #binding-cells = <0>;
            bindings = <&logos_kana_byo>, <&logos_kana_byo_pass>;
            mods = <LOGOS_KANA_MODS>;
            keep-mods = <LOGOS_KANA_MODS>;
        };

        logos_kana_rya_combo: logos_kana_rya_combo {
            compatible = "zmk,behavior-mod-morph";
            #binding-cells = <0>;
            bindings = <&logos_kana_rya>, <&logos_kana_rya_pass>;
            mods = <LOGOS_KANA_MODS>;
            keep-mods = <LOGOS_KANA_MODS>;
        };

        logos_kana_ryu_combo: logos_kana_ryu_combo {
            compatible = "zmk,behavior-mod-morph";
            #binding-cells = <0>;
            bindings = <&logos_kana_ryu>, <&logos_kana_ryu_pass>;
            mods = <LOGOS_KANA_MODS>;
            keep-mods = <LOGOS_KANA_MODS>;
        };

        logos_kana_ryo_combo: logos_kana_ryo_combo {
            compatible = "zmk,behavior-mod-morph";
            #binding-cells = <0>;
            bindings = <&logos_kana_ryo>, <&logos_kana_ryo_pass>;
            mods = <LOGOS_KANA_MODS>;
            keep-mods = <LOGOS_KANA_MODS>;
        };

        logos_kana_mya_combo: logos_kana_mya_combo {
            compatible = "zmk,behavior-mod-morph";
            #binding-cells = <0>;
            bindings = <&logos_kana_mya>, <&logos_kana_mya_pass>;
            mods = <LOGOS_KANA_MODS>;
            keep-mods = <LOGOS_KANA_MODS>;
        };

        logos_kana_myu_combo: logos_kana_myu_combo {
            compatible = "zmk,behavior-mod-morph";
            #binding-cells = <0>;
            bindings = <&logos_kana_myu>, <&logos_kana_myu_pass>;
            mods = <LOGOS_KANA_MODS>;
            keep-mods = <LOGOS_KANA_MODS>;
        };

        logos_kana_myo_combo: logos_kana_myo_combo {
            compatible = "zmk,behavior-mod-morph";
            #binding-cells = <0>;
            bindings = <&logos_kana_myo>, <&logos_kana_myo_pass>;
            mods = <LOGOS_KANA_MODS>;
            keep-mods = <LOGOS_KANA_MODS>;
        };

        logos_kana_vi_combo: logos_kana_vi_combo {
            compatible = "zmk,behavior-mod-morph";
            #binding-cells = <0>;
            bindings = <&logos_kana_vi>, <&logos_kana_vi_pass>;
            mods = <LOGOS_KANA_MODS>;
            keep-mods = <LOGOS_KANA_MODS>;
        };

        logos_kana_va_combo: logos_kana_va_combo {
            compatible = "zmk,behavior-mod-morph";
            #binding-cells = <0>;
            bindings = <&logos_kana_va>, <&logos_kana_va_pass>;
            mods = <LOGOS_KANA_MODS>;
            keep-mods = <LOGOS_KANA_MODS>;
        };

        logos_kana_che_combo: logos_kana_che_combo {
            compatible = "zmk,behavior-mod-morph";
            #binding-cells = <0>;
            bindings = <&logos_kana_che>, <&logos_kana_che_pass>;
            mods = <LOGOS_KANA_MODS>;
            keep-mods = <LOGOS_KANA_MODS>;
        };

        logos_kana_pya_combo: logos_kana_pya_combo {
            compatible = "zmk,behavior-mod-morph";
            #binding-cells = <0>;
            bindings = <&logos_kana_pya>, <&logos_kana_pya_pass>;
            mods = <LOGOS_KANA_MODS>;
            keep-mods = <LOGOS_KANA_MODS>;
        };

        logos_kana_pyu_combo: logos_kana_pyu_combo {
            compatible = "zmk,behavior-mod-morph";
            #binding-cells = <0>;
            bindings = <&logos_kana_pyu>, <&logos_kana_pyu_pass>;
            mods = <LOGOS_KANA_MODS>;
            keep-mods = <LOGOS_KANA_MODS>;
        };

        logos_kana_pyo_combo: logos_kana_pyo_combo {
            compatible = "zmk,behavior-mod-morph";
            #binding-cells = <0>;
            bindings = <&logos_kana_pyo>, <&logos_kana_pyo_pass>;
            mods = <LOGOS_KANA_MODS>;
            keep-mods = <LOGOS_KANA_MODS>;
        };

        logos_kana_fi_combo: logos_kana_fi_combo {
            compatible = "zmk,behavior-mod-morph";
            #binding-cells = <0>;
            bindings = <&logos_kana_fi>, <&logos_kana_fi_pass>;
            mods = <LOGOS_KANA_MODS>;
            keep-mods = <LOGOS_KANA_MODS>;
        };

        logos_kana_fa_combo: logos_kana_fa_combo {
            compatible = "zmk,behavior-mod-morph";
            #binding-cells = <0>;
            bindings = <&logos_kana_fa>, <&logos_kana_fa_pass>;
            mods = <LOGOS_KANA_MODS>;
            keep-mods = <LOGOS_KANA_MODS>;
        };

        logos_kana_fo_combo: logos_kana_fo_combo {
            compatible = "zmk,behavior-mod-morph";
            #binding-cells = <0>;
            bindings = <&logos_kana_fo>, <&logos_kana_fo_pass>;
            mods = <LOGOS_KANA_MODS>;
            keep-mods = <LOGOS_KANA_MODS>;
        };

        logos_kana_she_combo: logos_kana_she_combo {
            compatible = "zmk,behavior-mod-morph";
            #binding-cells = <0>;
            bindings = <&logos_kana_she>, <&logos_kana_she_pass>;
            mods = <LOGOS_KANA_MODS>;
            keep-mods = <LOGOS_KANA_MODS>;
        };

        logos_kana_je_combo: logos_kana_je_combo {
            compatible = "zmk,behavior-mod-morph";
            #binding-cells = <0>;
            bindings = <&logos_kana_je>, <&logos_kana_je_pass>;
            mods = <LOGOS_KANA_MODS>;
            keep-mods = <LOGOS_KANA_MODS>;
        };

        logos_kana_twu_combo: logos_kana_twu_combo {
            compatible = "zmk,behavior-mod-morph";
            #binding-cells = <0>;
            bindings = <&logos_kana_twu>, <&logos_kana_twu_pass>;
            mods = <LOGOS_KANA_MODS>;
            keep-mods = <LOGOS_KANA_MODS>;
        };

        logos_kana_dwu_combo: logos_kana_dwu_combo {
            compatible = "zmk,behavior-mod-morph";
            #binding-cells = <0>;
            bindings = <&logos_kana_dwu>, <&logos_kana_dwu_pass>;
            mods = <LOGOS_KANA_MODS>;
            keep-mods = <LOGOS_KANA_MODS>;
        };

        logos_kana_wi_combo: logos_kana_wi_combo {
            compatible = "zmk,behavior-mod-morph";
            #binding-cells = <0>;
            bindings = <&logos_kana_wi>, <&logos_kana_wi_pass>;
            mods = <LOGOS_KANA_MODS>;
            keep-mods = <LOGOS_KANA_MODS>;
        };

        logos_kana_we_combo: logos_kana_we_combo {
            compatible = "zmk,behavior-mod-morph";
            #binding-cells = <0>;
            bindings = <&logos_kana_we>, <&logos_kana_we_pass>;
            mods = <LOGOS_KANA_MODS>;
            keep-mods = <LOGOS_KANA_MODS>;
        };

        logos_kana_who_combo: logos_kana_who_combo {
            compatible = "zmk,behavior-mod-morph";
            #binding-cells = <0>;
            bindings = <&logos_kana_who>, <&logos_kana_who_pass>;
            mods = <LOGOS_KANA_MODS>;
            keep-mods = <LOGOS_KANA_MODS>;
        };

        logos_kana_ve_combo: logos_kana_ve_combo {
            compatible = "zmk,behavior-mod-morph";
            #binding-cells = <0>;
            bindings = <&logos_kana_ve>, <&logos_kana_ve_pass>;
            mods = <LOGOS_KANA_MODS>;
            keep-mods = <LOGOS_KANA_MODS>;
        };

        logos_kana_fe_combo: logos_kana_fe_combo {
            compatible = "zmk,behavior-mod-morph";
            #binding-cells = <0>;
            bindings = <&logos_kana_fe>, <&logos_kana_fe_pass>;
            mods = <LOGOS_KANA_MODS>;
            keep-mods = <LOGOS_KANA_MODS>;
        };

        logos_kana_vo_combo: logos_kana_vo_combo {
            compatible = "zmk,behavior-mod-morph";
            #binding-cells = <0>;
            bindings = <&logos_kana_vo>, <&logos_kana_vo_pass>;
            mods = <LOGOS_KANA_MODS>;
            keep-mods = <LOGOS_KANA_MODS>;
        };

    };

    macros {
        logos_kana_on: logos_kana_on {
            compatible = "zmk,behavior-macro";
            #binding-cells = <0>;
            wait-ms = <LOGOS_KANA_MACRO_WAIT_MS>;
            tap-ms = <LOGOS_KANA_MACRO_TAP_MS>;
            bindings = LOGOS_KANA_ON_BINDINGS;
        };

        logos_kana_off: logos_kana_off {
            compatible = "zmk,behavior-macro";
            #binding-cells = <0>;
            wait-ms = <LOGOS_KANA_MACRO_WAIT_MS>;
            tap-ms = <LOGOS_KANA_MACRO_TAP_MS>;
            bindings = LOGOS_KANA_OFF_BINDINGS;
        };

        logos_kana_se: logos_kana_se {
            compatible = "zmk,behavior-macro";
            #binding-cells = <0>;
            wait-ms = <LOGOS_KANA_MACRO_WAIT_MS>;
            tap-ms = <LOGOS_KANA_MACRO_TAP_MS>;
            bindings = <&kp S &kp E>;
        };

        logos_kana_sa: logos_kana_sa {
            compatible = "zmk,behavior-macro";
            #binding-cells = <0>;
            wait-ms = <LOGOS_KANA_MACRO_WAIT_MS>;
            tap-ms = <LOGOS_KANA_MACRO_TAP_MS>;
            bindings = <&kp S &kp A>;
        };

        logos_kana_ha: logos_kana_ha {
            compatible = "zmk,behavior-macro";
            #binding-cells = <0>;
            wait-ms = <LOGOS_KANA_MACRO_WAIT_MS>;
            tap-ms = <LOGOS_KANA_MACRO_TAP_MS>;
            bindings = <&kp H &kp A>;
        };

        logos_kana_te: logos_kana_te {
            compatible = "zmk,behavior-macro";
            #binding-cells = <0>;
            wait-ms = <LOGOS_KANA_MACRO_WAIT_MS>;
            tap-ms = <LOGOS_KANA_MACRO_TAP_MS>;
            bindings = <&kp T &kp E>;
        };

        logos_kana_wo: logos_kana_wo {
            compatible = "zmk,behavior-macro";
            #binding-cells = <0>;
            wait-ms = <LOGOS_KANA_MACRO_WAIT_MS>;
            tap-ms = <LOGOS_KANA_MACRO_TAP_MS>;
            bindings = <&kp W &kp O>;
        };

        logos_kana_ti: logos_kana_ti {
            compatible = "zmk,behavior-macro";
            #binding-cells = <0>;
            wait-ms = <LOGOS_KANA_MACRO_WAIT_MS>;
            tap-ms = <LOGOS_KANA_MACRO_TAP_MS>;
            bindings = <&kp T &kp I>;
        };

        logos_kana_tu: logos_kana_tu {
            compatible = "zmk,behavior-macro";
            #binding-cells = <0>;
            wait-ms = <LOGOS_KANA_MACRO_WAIT_MS>;
            tap-ms = <LOGOS_KANA_MACRO_TAP_MS>;
            bindings = <&kp T &kp U>;
        };

        logos_kana_ku: logos_kana_ku {
            compatible = "zmk,behavior-macro";
            #binding-cells = <0>;
            wait-ms = <LOGOS_KANA_MACRO_WAIT_MS>;
            tap-ms = <LOGOS_KANA_MACRO_TAP_MS>;
            bindings = <&kp K &kp U>;
        };

        logos_kana_xtu: logos_kana_xtu {
            compatible = "zmk,behavior-macro";
            #binding-cells = <0>;
            wait-ms = <LOGOS_KANA_MACRO_WAIT_MS>;
            tap-ms = <LOGOS_KANA_MACRO_TAP_MS>;
            bindings = <&kp X &kp T &kp U>;
        };

        logos_kana_hi: logos_kana_hi {
            compatible = "zmk,behavior-macro";
            #binding-cells = <0>;
            wait-ms = <LOGOS_KANA_MACRO_WAIT_MS>;
            tap-ms = <LOGOS_KANA_MACRO_TAP_MS>;
            bindings = <&kp H &kp I>;
        };

        logos_kana_ka: logos_kana_ka {
            compatible = "zmk,behavior-macro";
            #binding-cells = <0>;
            wait-ms = <LOGOS_KANA_MACRO_WAIT_MS>;
            tap-ms = <LOGOS_KANA_MACRO_TAP_MS>;
            bindings = <&kp K &kp A>;
        };

        logos_kana_to: logos_kana_to {
            compatible = "zmk,behavior-macro";
            #binding-cells = <0>;
            wait-ms = <LOGOS_KANA_MACRO_WAIT_MS>;
            tap-ms = <LOGOS_KANA_MACRO_TAP_MS>;
            bindings = <&kp T &kp O>;
        };

        logos_kana_ta: logos_kana_ta {
            compatible = "zmk,behavior-macro";
            #binding-cells = <0>;
            wait-ms = <LOGOS_KANA_MACRO_WAIT_MS>;
            tap-ms = <LOGOS_KANA_MACRO_TAP_MS>;
            bindings = <&kp T &kp A>;
        };

        logos_kana_no: logos_kana_no {
            compatible = "zmk,behavior-macro";
            #binding-cells = <0>;
            wait-ms = <LOGOS_KANA_MACRO_WAIT_MS>;
            tap-ms = <LOGOS_KANA_MACRO_TAP_MS>;
            bindings = <&kp N &kp O>;
        };

        logos_kana_ni: logos_kana_ni {
            compatible = "zmk,behavior-macro";
            #binding-cells = <0>;
            wait-ms = <LOGOS_KANA_MACRO_WAIT_MS>;
            tap-ms = <LOGOS_KANA_MACRO_TAP_MS>;
            bindings = <&kp N &kp I>;
        };

        logos_kana_comma: logos_kana_comma {
            compatible = "zmk,behavior-macro";
            #binding-cells = <0>;
            wait-ms = <LOGOS_KANA_MACRO_WAIT_MS>;
            tap-ms = <LOGOS_KANA_MACRO_TAP_MS>;
            bindings = <&kp COMMA>;
        };

        logos_kana_nn: logos_kana_nn {
            compatible = "zmk,behavior-macro";
            #binding-cells = <0>;
            wait-ms = <LOGOS_KANA_MACRO_WAIT_MS>;
            tap-ms = <LOGOS_KANA_MACRO_TAP_MS>;
            bindings = <&kp N &kp N>;
        };

        logos_kana_i: logos_kana_i {
            compatible = "zmk,behavior-macro";
            #binding-cells = <0>;
            wait-ms = <LOGOS_KANA_MACRO_WAIT_MS>;
            tap-ms = <LOGOS_KANA_MACRO_TAP_MS>;
            bindings = <&kp I>;
        };

        logos_kana_u: logos_kana_u {
            compatible = "zmk,behavior-macro";
            #binding-cells = <0>;
            wait-ms = <LOGOS_KANA_MACRO_WAIT_MS>;
            tap-ms = <LOGOS_KANA_MACRO_TAP_MS>;
            bindings = <&kp U>;
        };

        logos_kana_si: logos_kana_si {
            compatible = "zmk,behavior-macro";
            #binding-cells = <0>;
            wait-ms = <LOGOS_KANA_MACRO_WAIT_MS>;
            tap-ms = <LOGOS_KANA_MACRO_TAP_MS>;
            bindings = <&kp S &kp I>;
        };

        logos_kana_yo: logos_kana_yo {
            compatible = "zmk,behavior-macro";
            #binding-cells = <0>;
            wait-ms = <LOGOS_KANA_MACRO_WAIT_MS>;
            tap-ms = <LOGOS_KANA_MACRO_TAP_MS>;
            bindings = <&kp Y &kp O>;
        };

        logos_kana_da: logos_kana_da {
            compatible = "zmk,behavior-macro";
            #binding-cells = <0>;
            wait-ms = <LOGOS_KANA_MACRO_WAIT_MS>;
            tap-ms = <LOGOS_KANA_MACRO_TAP_MS>;
            bindings = <&kp D &kp A>;
        };

        logos_kana_do: logos_kana_do {
            compatible = "zmk,behavior-macro";
            #binding-cells = <0>;
            wait-ms = <LOGOS_KANA_MACRO_WAIT_MS>;
            tap-ms = <LOGOS_KANA_MACRO_TAP_MS>;
            bindings = <&kp D &kp O>;
        };

        logos_kana_ga: logos_kana_ga {
            compatible = "zmk,behavior-macro";
            #binding-cells = <0>;
            wait-ms = <LOGOS_KANA_MACRO_WAIT_MS>;
            tap-ms = <LOGOS_KANA_MACRO_TAP_MS>;
            bindings = <&kp G &kp A>;
        };

        logos_kana_ra: logos_kana_ra {
            compatible = "zmk,behavior-macro";
            #binding-cells = <0>;
            wait-ms = <LOGOS_KANA_MACRO_WAIT_MS>;
            tap-ms = <LOGOS_KANA_MACRO_TAP_MS>;
            bindings = <&kp R &kp A>;
        };

        logos_kana_wa: logos_kana_wa {
            compatible = "zmk,behavior-macro";
            #binding-cells = <0>;
            wait-ms = <LOGOS_KANA_MACRO_WAIT_MS>;
            tap-ms = <LOGOS_KANA_MACRO_TAP_MS>;
            bindings = <&kp W &kp A>;
        };

        logos_kana_ru: logos_kana_ru {
            compatible = "zmk,behavior-macro";
            #binding-cells = <0>;
            wait-ms = <LOGOS_KANA_MACRO_WAIT_MS>;
            tap-ms = <LOGOS_KANA_MACRO_TAP_MS>;
            bindings = <&kp R &kp U>;
        };

        logos_kana_long: logos_kana_long {
            compatible = "zmk,behavior-macro";
            #binding-cells = <0>;
            wait-ms = <LOGOS_KANA_MACRO_WAIT_MS>;
            tap-ms = <LOGOS_KANA_MACRO_TAP_MS>;
            bindings = <&kp MINUS>;
        };

        logos_kana_re: logos_kana_re {
            compatible = "zmk,behavior-macro";
            #binding-cells = <0>;
            wait-ms = <LOGOS_KANA_MACRO_WAIT_MS>;
            tap-ms = <LOGOS_KANA_MACRO_TAP_MS>;
            bindings = <&kp R &kp E>;
        };

        logos_kana_e: logos_kana_e {
            compatible = "zmk,behavior-macro";
            #binding-cells = <0>;
            wait-ms = <LOGOS_KANA_MACRO_WAIT_MS>;
            tap-ms = <LOGOS_KANA_MACRO_TAP_MS>;
            bindings = <&kp E>;
        };

        logos_kana_di: logos_kana_di {
            compatible = "zmk,behavior-macro";
            #binding-cells = <0>;
            wait-ms = <LOGOS_KANA_MACRO_WAIT_MS>;
            tap-ms = <LOGOS_KANA_MACRO_TAP_MS>;
            bindings = <&kp D &kp I>;
        };

        logos_kana_di_pass: logos_kana_di_pass {
            compatible = "zmk,behavior-macro";
            #binding-cells = <0>;
            wait-ms = <LOGOS_KANA_MACRO_WAIT_MS>;
            tap-ms = <LOGOS_KANA_MACRO_TAP_MS>;
            bindings = <&kp LOGOS_KANA_FALLBACK_K &kp LOGOS_KANA_FALLBACK_Q>;
        };

        logos_kana_ge: logos_kana_ge {
            compatible = "zmk,behavior-macro";
            #binding-cells = <0>;
            wait-ms = <LOGOS_KANA_MACRO_WAIT_MS>;
            tap-ms = <LOGOS_KANA_MACRO_TAP_MS>;
            bindings = <&kp G &kp E>;
        };

        logos_kana_ge_pass: logos_kana_ge_pass {
            compatible = "zmk,behavior-macro";
            #binding-cells = <0>;
            wait-ms = <LOGOS_KANA_MACRO_WAIT_MS>;
            tap-ms = <LOGOS_KANA_MACRO_TAP_MS>;
            bindings = <&kp LOGOS_KANA_FALLBACK_K &kp LOGOS_KANA_FALLBACK_W>;
        };

        logos_kana_ho: logos_kana_ho {
            compatible = "zmk,behavior-macro";
            #binding-cells = <0>;
            wait-ms = <LOGOS_KANA_MACRO_WAIT_MS>;
            tap-ms = <LOGOS_KANA_MACRO_TAP_MS>;
            bindings = <&kp H &kp O>;
        };

        logos_kana_ho_pass: logos_kana_ho_pass {
            compatible = "zmk,behavior-macro";
            #binding-cells = <0>;
            wait-ms = <LOGOS_KANA_MACRO_WAIT_MS>;
            tap-ms = <LOGOS_KANA_MACRO_TAP_MS>;
            bindings = <&kp LOGOS_KANA_FALLBACK_K &kp LOGOS_KANA_FALLBACK_E>;
        };

        logos_kana_gi: logos_kana_gi {
            compatible = "zmk,behavior-macro";
            #binding-cells = <0>;
            wait-ms = <LOGOS_KANA_MACRO_WAIT_MS>;
            tap-ms = <LOGOS_KANA_MACRO_TAP_MS>;
            bindings = <&kp G &kp I>;
        };

        logos_kana_gi_pass: logos_kana_gi_pass {
            compatible = "zmk,behavior-macro";
            #binding-cells = <0>;
            wait-ms = <LOGOS_KANA_MACRO_WAIT_MS>;
            tap-ms = <LOGOS_KANA_MACRO_TAP_MS>;
            bindings = <&kp LOGOS_KANA_FALLBACK_K &kp LOGOS_KANA_FALLBACK_R>;
        };

        logos_kana_ze: logos_kana_ze {
            compatible = "zmk,behavior-macro";
            #binding-cells = <0>;
            wait-ms = <LOGOS_KANA_MACRO_WAIT_MS>;
            tap-ms = <LOGOS_KANA_MACRO_TAP_MS>;
            bindings = <&kp Z &kp E>;
        };

        logos_kana_ze_pass: logos_kana_ze_pass {
            compatible = "zmk,behavior-macro";
            #binding-cells = <0>;
            wait-ms = <LOGOS_KANA_MACRO_WAIT_MS>;
            tap-ms = <LOGOS_KANA_MACRO_TAP_MS>;
            bindings = <&kp LOGOS_KANA_FALLBACK_K &kp LOGOS_KANA_FALLBACK_T>;
        };

        logos_kana_du: logos_kana_du {
            compatible = "zmk,behavior-macro";
            #binding-cells = <0>;
            wait-ms = <LOGOS_KANA_MACRO_WAIT_MS>;
            tap-ms = <LOGOS_KANA_MACRO_TAP_MS>;
            bindings = <&kp D &kp U>;
        };

        logos_kana_du_pass: logos_kana_du_pass {
            compatible = "zmk,behavior-macro";
            #binding-cells = <0>;
            wait-ms = <LOGOS_KANA_MACRO_WAIT_MS>;
            tap-ms = <LOGOS_KANA_MACRO_TAP_MS>;
            bindings = <&kp LOGOS_KANA_FALLBACK_D &kp LOGOS_KANA_FALLBACK_Y>;
        };

        logos_kana_yu: logos_kana_yu {
            compatible = "zmk,behavior-macro";
            #binding-cells = <0>;
            wait-ms = <LOGOS_KANA_MACRO_WAIT_MS>;
            tap-ms = <LOGOS_KANA_MACRO_TAP_MS>;
            bindings = <&kp Y &kp U>;
        };

        logos_kana_yu_pass: logos_kana_yu_pass {
            compatible = "zmk,behavior-macro";
            #binding-cells = <0>;
            wait-ms = <LOGOS_KANA_MACRO_WAIT_MS>;
            tap-ms = <LOGOS_KANA_MACRO_TAP_MS>;
            bindings = <&kp LOGOS_KANA_FALLBACK_D &kp LOGOS_KANA_FALLBACK_U>;
        };

        logos_kana_hu: logos_kana_hu {
            compatible = "zmk,behavior-macro";
            #binding-cells = <0>;
            wait-ms = <LOGOS_KANA_MACRO_WAIT_MS>;
            tap-ms = <LOGOS_KANA_MACRO_TAP_MS>;
            bindings = <&kp H &kp U>;
        };

        logos_kana_hu_pass: logos_kana_hu_pass {
            compatible = "zmk,behavior-macro";
            #binding-cells = <0>;
            wait-ms = <LOGOS_KANA_MACRO_WAIT_MS>;
            tap-ms = <LOGOS_KANA_MACRO_TAP_MS>;
            bindings = <&kp LOGOS_KANA_FALLBACK_D &kp LOGOS_KANA_FALLBACK_I>;
        };

        logos_kana_bi: logos_kana_bi {
            compatible = "zmk,behavior-macro";
            #binding-cells = <0>;
            wait-ms = <LOGOS_KANA_MACRO_WAIT_MS>;
            tap-ms = <LOGOS_KANA_MACRO_TAP_MS>;
            bindings = <&kp B &kp I>;
        };

        logos_kana_bi_pass: logos_kana_bi_pass {
            compatible = "zmk,behavior-macro";
            #binding-cells = <0>;
            wait-ms = <LOGOS_KANA_MACRO_WAIT_MS>;
            tap-ms = <LOGOS_KANA_MACRO_TAP_MS>;
            bindings = <&kp LOGOS_KANA_FALLBACK_D &kp LOGOS_KANA_FALLBACK_O>;
        };

        logos_kana_vu: logos_kana_vu {
            compatible = "zmk,behavior-macro";
            #binding-cells = <0>;
            wait-ms = <LOGOS_KANA_MACRO_WAIT_MS>;
            tap-ms = <LOGOS_KANA_MACRO_TAP_MS>;
            bindings = <&kp V &kp U>;
        };

        logos_kana_vu_pass: logos_kana_vu_pass {
            compatible = "zmk,behavior-macro";
            #binding-cells = <0>;
            wait-ms = <LOGOS_KANA_MACRO_WAIT_MS>;
            tap-ms = <LOGOS_KANA_MACRO_TAP_MS>;
            bindings = <&kp LOGOS_KANA_FALLBACK_D &kp LOGOS_KANA_FALLBACK_P>;
        };

        logos_kana_ke: logos_kana_ke {
            compatible = "zmk,behavior-macro";
            #binding-cells = <0>;
            wait-ms = <LOGOS_KANA_MACRO_WAIT_MS>;
            tap-ms = <LOGOS_KANA_MACRO_TAP_MS>;
            bindings = <&kp K &kp E>;
        };

        logos_kana_ke_pass: logos_kana_ke_pass {
            compatible = "zmk,behavior-macro";
            #binding-cells = <0>;
            wait-ms = <LOGOS_KANA_MACRO_WAIT_MS>;
            tap-ms = <LOGOS_KANA_MACRO_TAP_MS>;
            bindings = <&kp LOGOS_KANA_FALLBACK_K &kp LOGOS_KANA_FALLBACK_A>;
        };

        logos_kana_na: logos_kana_na {
            compatible = "zmk,behavior-macro";
            #binding-cells = <0>;
            wait-ms = <LOGOS_KANA_MACRO_WAIT_MS>;
            tap-ms = <LOGOS_KANA_MACRO_TAP_MS>;
            bindings = <&kp N &kp A>;
        };

        logos_kana_na_pass: logos_kana_na_pass {
            compatible = "zmk,behavior-macro";
            #binding-cells = <0>;
            wait-ms = <LOGOS_KANA_MACRO_WAIT_MS>;
            tap-ms = <LOGOS_KANA_MACRO_TAP_MS>;
            bindings = <&kp LOGOS_KANA_FALLBACK_K &kp LOGOS_KANA_FALLBACK_S>;
        };

        logos_kana_ko: logos_kana_ko {
            compatible = "zmk,behavior-macro";
            #binding-cells = <0>;
            wait-ms = <LOGOS_KANA_MACRO_WAIT_MS>;
            tap-ms = <LOGOS_KANA_MACRO_TAP_MS>;
            bindings = <&kp K &kp O>;
        };

        logos_kana_ko_pass: logos_kana_ko_pass {
            compatible = "zmk,behavior-macro";
            #binding-cells = <0>;
            wait-ms = <LOGOS_KANA_MACRO_WAIT_MS>;
            tap-ms = <LOGOS_KANA_MACRO_TAP_MS>;
            bindings = <&kp LOGOS_KANA_FALLBACK_K &kp LOGOS_KANA_FALLBACK_D>;
        };

        logos_kana_period: logos_kana_period {
            compatible = "zmk,behavior-macro";
            #binding-cells = <0>;
            wait-ms = <LOGOS_KANA_MACRO_WAIT_MS>;
            tap-ms = <LOGOS_KANA_MACRO_TAP_MS>;
            bindings = <&kp DOT>;
        };

        logos_kana_period_pass: logos_kana_period_pass {
            compatible = "zmk,behavior-macro";
            #binding-cells = <0>;
            wait-ms = <LOGOS_KANA_MACRO_WAIT_MS>;
            tap-ms = <LOGOS_KANA_MACRO_TAP_MS>;
            bindings = <&kp LOGOS_KANA_FALLBACK_K &kp LOGOS_KANA_FALLBACK_F>;
        };

        logos_kana_zi: logos_kana_zi {
            compatible = "zmk,behavior-macro";
            #binding-cells = <0>;
            wait-ms = <LOGOS_KANA_MACRO_WAIT_MS>;
            tap-ms = <LOGOS_KANA_MACRO_TAP_MS>;
            bindings = <&kp Z &kp I>;
        };

        logos_kana_zi_pass: logos_kana_zi_pass {
            compatible = "zmk,behavior-macro";
            #binding-cells = <0>;
            wait-ms = <LOGOS_KANA_MACRO_WAIT_MS>;
            tap-ms = <LOGOS_KANA_MACRO_TAP_MS>;
            bindings = <&kp LOGOS_KANA_FALLBACK_K &kp LOGOS_KANA_FALLBACK_G>;
        };

        logos_kana_so: logos_kana_so {
            compatible = "zmk,behavior-macro";
            #binding-cells = <0>;
            wait-ms = <LOGOS_KANA_MACRO_WAIT_MS>;
            tap-ms = <LOGOS_KANA_MACRO_TAP_MS>;
            bindings = <&kp S &kp O>;
        };

        logos_kana_so_pass: logos_kana_so_pass {
            compatible = "zmk,behavior-macro";
            #binding-cells = <0>;
            wait-ms = <LOGOS_KANA_MACRO_WAIT_MS>;
            tap-ms = <LOGOS_KANA_MACRO_TAP_MS>;
            bindings = <&kp LOGOS_KANA_FALLBACK_D &kp LOGOS_KANA_FALLBACK_H>;
        };

        logos_kana_o: logos_kana_o {
            compatible = "zmk,behavior-macro";
            #binding-cells = <0>;
            wait-ms = <LOGOS_KANA_MACRO_WAIT_MS>;
            tap-ms = <LOGOS_KANA_MACRO_TAP_MS>;
            bindings = <&kp O>;
        };

        logos_kana_o_pass: logos_kana_o_pass {
            compatible = "zmk,behavior-macro";
            #binding-cells = <0>;
            wait-ms = <LOGOS_KANA_MACRO_WAIT_MS>;
            tap-ms = <LOGOS_KANA_MACRO_TAP_MS>;
            bindings = <&kp LOGOS_KANA_FALLBACK_D &kp LOGOS_KANA_FALLBACK_J>;
        };

        logos_kana_a: logos_kana_a {
            compatible = "zmk,behavior-macro";
            #binding-cells = <0>;
            wait-ms = <LOGOS_KANA_MACRO_WAIT_MS>;
            tap-ms = <LOGOS_KANA_MACRO_TAP_MS>;
            bindings = <&kp A>;
        };

        logos_kana_a_pass: logos_kana_a_pass {
            compatible = "zmk,behavior-macro";
            #binding-cells = <0>;
            wait-ms = <LOGOS_KANA_MACRO_WAIT_MS>;
            tap-ms = <LOGOS_KANA_MACRO_TAP_MS>;
            bindings = <&kp LOGOS_KANA_FALLBACK_D &kp LOGOS_KANA_FALLBACK_SEMI>;
        };

        logos_kana_pi: logos_kana_pi {
            compatible = "zmk,behavior-macro";
            #binding-cells = <0>;
            wait-ms = <LOGOS_KANA_MACRO_WAIT_MS>;
            tap-ms = <LOGOS_KANA_MACRO_TAP_MS>;
            bindings = <&kp P &kp I>;
        };

        logos_kana_pi_pass: logos_kana_pi_pass {
            compatible = "zmk,behavior-macro";
            #binding-cells = <0>;
            wait-ms = <LOGOS_KANA_MACRO_WAIT_MS>;
            tap-ms = <LOGOS_KANA_MACRO_TAP_MS>;
            bindings = <&kp LOGOS_KANA_FALLBACK_K &kp LOGOS_KANA_FALLBACK_Z>;
        };

        logos_kana_po: logos_kana_po {
            compatible = "zmk,behavior-macro";
            #binding-cells = <0>;
            wait-ms = <LOGOS_KANA_MACRO_WAIT_MS>;
            tap-ms = <LOGOS_KANA_MACRO_TAP_MS>;
            bindings = <&kp P &kp O>;
        };

        logos_kana_po_pass: logos_kana_po_pass {
            compatible = "zmk,behavior-macro";
            #binding-cells = <0>;
            wait-ms = <LOGOS_KANA_MACRO_WAIT_MS>;
            tap-ms = <LOGOS_KANA_MACRO_TAP_MS>;
            bindings = <&kp LOGOS_KANA_FALLBACK_K &kp LOGOS_KANA_FALLBACK_X>;
        };

        logos_kana_ne: logos_kana_ne {
            compatible = "zmk,behavior-macro";
            #binding-cells = <0>;
            wait-ms = <LOGOS_KANA_MACRO_WAIT_MS>;
            tap-ms = <LOGOS_KANA_MACRO_TAP_MS>;
            bindings = <&kp N &kp E>;
        };

        logos_kana_ne_pass: logos_kana_ne_pass {
            compatible = "zmk,behavior-macro";
            #binding-cells = <0>;
            wait-ms = <LOGOS_KANA_MACRO_WAIT_MS>;
            tap-ms = <LOGOS_KANA_MACRO_TAP_MS>;
            bindings = <&kp LOGOS_KANA_FALLBACK_K &kp LOGOS_KANA_FALLBACK_C>;
        };

        logos_kana_ba: logos_kana_ba {
            compatible = "zmk,behavior-macro";
            #binding-cells = <0>;
            wait-ms = <LOGOS_KANA_MACRO_WAIT_MS>;
            tap-ms = <LOGOS_KANA_MACRO_TAP_MS>;
            bindings = <&kp B &kp A>;
        };

        logos_kana_ba_pass: logos_kana_ba_pass {
            compatible = "zmk,behavior-macro";
            #binding-cells = <0>;
            wait-ms = <LOGOS_KANA_MACRO_WAIT_MS>;
            tap-ms = <LOGOS_KANA_MACRO_TAP_MS>;
            bindings = <&kp LOGOS_KANA_FALLBACK_K &kp LOGOS_KANA_FALLBACK_V>;
        };

        logos_kana_pa: logos_kana_pa {
            compatible = "zmk,behavior-macro";
            #binding-cells = <0>;
            wait-ms = <LOGOS_KANA_MACRO_WAIT_MS>;
            tap-ms = <LOGOS_KANA_MACRO_TAP_MS>;
            bindings = <&kp P &kp A>;
        };

        logos_kana_pa_pass: logos_kana_pa_pass {
            compatible = "zmk,behavior-macro";
            #binding-cells = <0>;
            wait-ms = <LOGOS_KANA_MACRO_WAIT_MS>;
            tap-ms = <LOGOS_KANA_MACRO_TAP_MS>;
            bindings = <&kp LOGOS_KANA_FALLBACK_K &kp LOGOS_KANA_FALLBACK_B>;
        };

        logos_kana_nu: logos_kana_nu {
            compatible = "zmk,behavior-macro";
            #binding-cells = <0>;
            wait-ms = <LOGOS_KANA_MACRO_WAIT_MS>;
            tap-ms = <LOGOS_KANA_MACRO_TAP_MS>;
            bindings = <&kp N &kp U>;
        };

        logos_kana_nu_pass: logos_kana_nu_pass {
            compatible = "zmk,behavior-macro";
            #binding-cells = <0>;
            wait-ms = <LOGOS_KANA_MACRO_WAIT_MS>;
            tap-ms = <LOGOS_KANA_MACRO_TAP_MS>;
            bindings = <&kp LOGOS_KANA_FALLBACK_D &kp LOGOS_KANA_FALLBACK_N>;
        };

        logos_kana_mi: logos_kana_mi {
            compatible = "zmk,behavior-macro";
            #binding-cells = <0>;
            wait-ms = <LOGOS_KANA_MACRO_WAIT_MS>;
            tap-ms = <LOGOS_KANA_MACRO_TAP_MS>;
            bindings = <&kp M &kp I>;
        };

        logos_kana_mi_pass: logos_kana_mi_pass {
            compatible = "zmk,behavior-macro";
            #binding-cells = <0>;
            wait-ms = <LOGOS_KANA_MACRO_WAIT_MS>;
            tap-ms = <LOGOS_KANA_MACRO_TAP_MS>;
            bindings = <&kp LOGOS_KANA_FALLBACK_D &kp LOGOS_KANA_FALLBACK_M>;
        };

        logos_kana_gu: logos_kana_gu {
            compatible = "zmk,behavior-macro";
            #binding-cells = <0>;
            wait-ms = <LOGOS_KANA_MACRO_WAIT_MS>;
            tap-ms = <LOGOS_KANA_MACRO_TAP_MS>;
            bindings = <&kp G &kp U>;
        };

        logos_kana_gu_pass: logos_kana_gu_pass {
            compatible = "zmk,behavior-macro";
            #binding-cells = <0>;
            wait-ms = <LOGOS_KANA_MACRO_WAIT_MS>;
            tap-ms = <LOGOS_KANA_MACRO_TAP_MS>;
            bindings = <&kp LOGOS_KANA_FALLBACK_D &kp LOGOS_KANA_FALLBACK_COMMA>;
        };

        logos_kana_dhi: logos_kana_dhi {
            compatible = "zmk,behavior-macro";
            #binding-cells = <0>;
            wait-ms = <LOGOS_KANA_MACRO_WAIT_MS>;
            tap-ms = <LOGOS_KANA_MACRO_TAP_MS>;
            bindings = <&kp D &kp H &kp I>;
        };

        logos_kana_dhi_pass: logos_kana_dhi_pass {
            compatible = "zmk,behavior-macro";
            #binding-cells = <0>;
            wait-ms = <LOGOS_KANA_MACRO_WAIT_MS>;
            tap-ms = <LOGOS_KANA_MACRO_TAP_MS>;
            bindings = <&kp LOGOS_KANA_FALLBACK_D &kp LOGOS_KANA_FALLBACK_DOT>;
        };

        logos_kana_pu: logos_kana_pu {
            compatible = "zmk,behavior-macro";
            #binding-cells = <0>;
            wait-ms = <LOGOS_KANA_MACRO_WAIT_MS>;
            tap-ms = <LOGOS_KANA_MACRO_TAP_MS>;
            bindings = <&kp P &kp U>;
        };

        logos_kana_pu_pass: logos_kana_pu_pass {
            compatible = "zmk,behavior-macro";
            #binding-cells = <0>;
            wait-ms = <LOGOS_KANA_MACRO_WAIT_MS>;
            tap-ms = <LOGOS_KANA_MACRO_TAP_MS>;
            bindings = <&kp LOGOS_KANA_FALLBACK_D &kp LOGOS_KANA_FALLBACK_SLASH>;
        };

        logos_kana_xa: logos_kana_xa {
            compatible = "zmk,behavior-macro";
            #binding-cells = <0>;
            wait-ms = <LOGOS_KANA_MACRO_WAIT_MS>;
            tap-ms = <LOGOS_KANA_MACRO_TAP_MS>;
            bindings = <&kp X &kp A>;
        };

        logos_kana_xa_pass: logos_kana_xa_pass {
            compatible = "zmk,behavior-macro";
            #binding-cells = <0>;
            wait-ms = <LOGOS_KANA_MACRO_WAIT_MS>;
            tap-ms = <LOGOS_KANA_MACRO_TAP_MS>;
            bindings = <&kp LOGOS_KANA_FALLBACK_L &kp LOGOS_KANA_FALLBACK_Q>;
        };

        logos_kana_me: logos_kana_me {
            compatible = "zmk,behavior-macro";
            #binding-cells = <0>;
            wait-ms = <LOGOS_KANA_MACRO_WAIT_MS>;
            tap-ms = <LOGOS_KANA_MACRO_TAP_MS>;
            bindings = <&kp M &kp E>;
        };

        logos_kana_me_pass: logos_kana_me_pass {
            compatible = "zmk,behavior-macro";
            #binding-cells = <0>;
            wait-ms = <LOGOS_KANA_MACRO_WAIT_MS>;
            tap-ms = <LOGOS_KANA_MACRO_TAP_MS>;
            bindings = <&kp LOGOS_KANA_FALLBACK_L &kp LOGOS_KANA_FALLBACK_W>;
        };

        logos_kana_bu: logos_kana_bu {
            compatible = "zmk,behavior-macro";
            #binding-cells = <0>;
            wait-ms = <LOGOS_KANA_MACRO_WAIT_MS>;
            tap-ms = <LOGOS_KANA_MACRO_TAP_MS>;
            bindings = <&kp B &kp U>;
        };

        logos_kana_bu_pass: logos_kana_bu_pass {
            compatible = "zmk,behavior-macro";
            #binding-cells = <0>;
            wait-ms = <LOGOS_KANA_MACRO_WAIT_MS>;
            tap-ms = <LOGOS_KANA_MACRO_TAP_MS>;
            bindings = <&kp LOGOS_KANA_FALLBACK_L &kp LOGOS_KANA_FALLBACK_E>;
        };

        logos_kana_za: logos_kana_za {
            compatible = "zmk,behavior-macro";
            #binding-cells = <0>;
            wait-ms = <LOGOS_KANA_MACRO_WAIT_MS>;
            tap-ms = <LOGOS_KANA_MACRO_TAP_MS>;
            bindings = <&kp Z &kp A>;
        };

        logos_kana_za_pass: logos_kana_za_pass {
            compatible = "zmk,behavior-macro";
            #binding-cells = <0>;
            wait-ms = <LOGOS_KANA_MACRO_WAIT_MS>;
            tap-ms = <LOGOS_KANA_MACRO_TAP_MS>;
            bindings = <&kp LOGOS_KANA_FALLBACK_L &kp LOGOS_KANA_FALLBACK_R>;
        };

        logos_kana_xi: logos_kana_xi {
            compatible = "zmk,behavior-macro";
            #binding-cells = <0>;
            wait-ms = <LOGOS_KANA_MACRO_WAIT_MS>;
            tap-ms = <LOGOS_KANA_MACRO_TAP_MS>;
            bindings = <&kp X &kp I>;
        };

        logos_kana_xi_pass: logos_kana_xi_pass {
            compatible = "zmk,behavior-macro";
            #binding-cells = <0>;
            wait-ms = <LOGOS_KANA_MACRO_WAIT_MS>;
            tap-ms = <LOGOS_KANA_MACRO_TAP_MS>;
            bindings = <&kp LOGOS_KANA_FALLBACK_L &kp LOGOS_KANA_FALLBACK_T>;
        };

        logos_kana_xu: logos_kana_xu {
            compatible = "zmk,behavior-macro";
            #binding-cells = <0>;
            wait-ms = <LOGOS_KANA_MACRO_WAIT_MS>;
            tap-ms = <LOGOS_KANA_MACRO_TAP_MS>;
            bindings = <&kp X &kp U>;
        };

        logos_kana_xu_pass: logos_kana_xu_pass {
            compatible = "zmk,behavior-macro";
            #binding-cells = <0>;
            wait-ms = <LOGOS_KANA_MACRO_WAIT_MS>;
            tap-ms = <LOGOS_KANA_MACRO_TAP_MS>;
            bindings = <&kp LOGOS_KANA_FALLBACK_S &kp LOGOS_KANA_FALLBACK_Y>;
        };

        logos_kana_zo: logos_kana_zo {
            compatible = "zmk,behavior-macro";
            #binding-cells = <0>;
            wait-ms = <LOGOS_KANA_MACRO_WAIT_MS>;
            tap-ms = <LOGOS_KANA_MACRO_TAP_MS>;
            bindings = <&kp Z &kp O>;
        };

        logos_kana_zo_pass: logos_kana_zo_pass {
            compatible = "zmk,behavior-macro";
            #binding-cells = <0>;
            wait-ms = <LOGOS_KANA_MACRO_WAIT_MS>;
            tap-ms = <LOGOS_KANA_MACRO_TAP_MS>;
            bindings = <&kp LOGOS_KANA_FALLBACK_S &kp LOGOS_KANA_FALLBACK_U>;
        };

        logos_kana_go: logos_kana_go {
            compatible = "zmk,behavior-macro";
            #binding-cells = <0>;
            wait-ms = <LOGOS_KANA_MACRO_WAIT_MS>;
            tap-ms = <LOGOS_KANA_MACRO_TAP_MS>;
            bindings = <&kp G &kp O>;
        };

        logos_kana_go_pass: logos_kana_go_pass {
            compatible = "zmk,behavior-macro";
            #binding-cells = <0>;
            wait-ms = <LOGOS_KANA_MACRO_WAIT_MS>;
            tap-ms = <LOGOS_KANA_MACRO_TAP_MS>;
            bindings = <&kp LOGOS_KANA_FALLBACK_S &kp LOGOS_KANA_FALLBACK_I>;
        };

        logos_kana_be: logos_kana_be {
            compatible = "zmk,behavior-macro";
            #binding-cells = <0>;
            wait-ms = <LOGOS_KANA_MACRO_WAIT_MS>;
            tap-ms = <LOGOS_KANA_MACRO_TAP_MS>;
            bindings = <&kp B &kp E>;
        };

        logos_kana_be_pass: logos_kana_be_pass {
            compatible = "zmk,behavior-macro";
            #binding-cells = <0>;
            wait-ms = <LOGOS_KANA_MACRO_WAIT_MS>;
            tap-ms = <LOGOS_KANA_MACRO_TAP_MS>;
            bindings = <&kp LOGOS_KANA_FALLBACK_S &kp LOGOS_KANA_FALLBACK_O>;
        };

        logos_kana_xe: logos_kana_xe {
            compatible = "zmk,behavior-macro";
            #binding-cells = <0>;
            wait-ms = <LOGOS_KANA_MACRO_WAIT_MS>;
            tap-ms = <LOGOS_KANA_MACRO_TAP_MS>;
            bindings = <&kp X &kp E>;
        };

        logos_kana_xe_pass: logos_kana_xe_pass {
            compatible = "zmk,behavior-macro";
            #binding-cells = <0>;
            wait-ms = <LOGOS_KANA_MACRO_WAIT_MS>;
            tap-ms = <LOGOS_KANA_MACRO_TAP_MS>;
            bindings = <&kp LOGOS_KANA_FALLBACK_S &kp LOGOS_KANA_FALLBACK_P>;
        };

        logos_kana_ki: logos_kana_ki {
            compatible = "zmk,behavior-macro";
            #binding-cells = <0>;
            wait-ms = <LOGOS_KANA_MACRO_WAIT_MS>;
            tap-ms = <LOGOS_KANA_MACRO_TAP_MS>;
            bindings = <&kp K &kp I>;
        };

        logos_kana_ki_pass: logos_kana_ki_pass {
            compatible = "zmk,behavior-macro";
            #binding-cells = <0>;
            wait-ms = <LOGOS_KANA_MACRO_WAIT_MS>;
            tap-ms = <LOGOS_KANA_MACRO_TAP_MS>;
            bindings = <&kp LOGOS_KANA_FALLBACK_L &kp LOGOS_KANA_FALLBACK_A>;
        };

        logos_kana_ri: logos_kana_ri {
            compatible = "zmk,behavior-macro";
            #binding-cells = <0>;
            wait-ms = <LOGOS_KANA_MACRO_WAIT_MS>;
            tap-ms = <LOGOS_KANA_MACRO_TAP_MS>;
            bindings = <&kp R &kp I>;
        };

        logos_kana_ri_pass: logos_kana_ri_pass {
            compatible = "zmk,behavior-macro";
            #binding-cells = <0>;
            wait-ms = <LOGOS_KANA_MACRO_WAIT_MS>;
            tap-ms = <LOGOS_KANA_MACRO_TAP_MS>;
            bindings = <&kp LOGOS_KANA_FALLBACK_L &kp LOGOS_KANA_FALLBACK_S>;
        };

        logos_kana_su: logos_kana_su {
            compatible = "zmk,behavior-macro";
            #binding-cells = <0>;
            wait-ms = <LOGOS_KANA_MACRO_WAIT_MS>;
            tap-ms = <LOGOS_KANA_MACRO_TAP_MS>;
            bindings = <&kp S &kp U>;
        };

        logos_kana_su_pass: logos_kana_su_pass {
            compatible = "zmk,behavior-macro";
            #binding-cells = <0>;
            wait-ms = <LOGOS_KANA_MACRO_WAIT_MS>;
            tap-ms = <LOGOS_KANA_MACRO_TAP_MS>;
            bindings = <&kp LOGOS_KANA_FALLBACK_L &kp LOGOS_KANA_FALLBACK_D>;
        };

        logos_kana_de: logos_kana_de {
            compatible = "zmk,behavior-macro";
            #binding-cells = <0>;
            wait-ms = <LOGOS_KANA_MACRO_WAIT_MS>;
            tap-ms = <LOGOS_KANA_MACRO_TAP_MS>;
            bindings = <&kp D &kp E>;
        };

        logos_kana_de_pass: logos_kana_de_pass {
            compatible = "zmk,behavior-macro";
            #binding-cells = <0>;
            wait-ms = <LOGOS_KANA_MACRO_WAIT_MS>;
            tap-ms = <LOGOS_KANA_MACRO_TAP_MS>;
            bindings = <&kp LOGOS_KANA_FALLBACK_L &kp LOGOS_KANA_FALLBACK_F>;
        };

        logos_kana_ya: logos_kana_ya {
            compatible = "zmk,behavior-macro";
            #binding-cells = <0>;
            wait-ms = <LOGOS_KANA_MACRO_WAIT_MS>;
            tap-ms = <LOGOS_KANA_MACRO_TAP_MS>;
            bindings = <&kp Y &kp A>;
        };

        logos_kana_ya_pass: logos_kana_ya_pass {
            compatible = "zmk,behavior-macro";
            #binding-cells = <0>;
            wait-ms = <LOGOS_KANA_MACRO_WAIT_MS>;
            tap-ms = <LOGOS_KANA_MACRO_TAP_MS>;
            bindings = <&kp LOGOS_KANA_FALLBACK_L &kp LOGOS_KANA_FALLBACK_G>;
        };

        logos_kana_ro: logos_kana_ro {
            compatible = "zmk,behavior-macro";
            #binding-cells = <0>;
            wait-ms = <LOGOS_KANA_MACRO_WAIT_MS>;
            tap-ms = <LOGOS_KANA_MACRO_TAP_MS>;
            bindings = <&kp R &kp O>;
        };

        logos_kana_ro_pass: logos_kana_ro_pass {
            compatible = "zmk,behavior-macro";
            #binding-cells = <0>;
            wait-ms = <LOGOS_KANA_MACRO_WAIT_MS>;
            tap-ms = <LOGOS_KANA_MACRO_TAP_MS>;
            bindings = <&kp LOGOS_KANA_FALLBACK_S &kp LOGOS_KANA_FALLBACK_H>;
        };

        logos_kana_ma: logos_kana_ma {
            compatible = "zmk,behavior-macro";
            #binding-cells = <0>;
            wait-ms = <LOGOS_KANA_MACRO_WAIT_MS>;
            tap-ms = <LOGOS_KANA_MACRO_TAP_MS>;
            bindings = <&kp M &kp A>;
        };

        logos_kana_ma_pass: logos_kana_ma_pass {
            compatible = "zmk,behavior-macro";
            #binding-cells = <0>;
            wait-ms = <LOGOS_KANA_MACRO_WAIT_MS>;
            tap-ms = <LOGOS_KANA_MACRO_TAP_MS>;
            bindings = <&kp LOGOS_KANA_FALLBACK_S &kp LOGOS_KANA_FALLBACK_J>;
        };

        logos_kana_mo: logos_kana_mo {
            compatible = "zmk,behavior-macro";
            #binding-cells = <0>;
            wait-ms = <LOGOS_KANA_MACRO_WAIT_MS>;
            tap-ms = <LOGOS_KANA_MACRO_TAP_MS>;
            bindings = <&kp M &kp O>;
        };

        logos_kana_mo_pass: logos_kana_mo_pass {
            compatible = "zmk,behavior-macro";
            #binding-cells = <0>;
            wait-ms = <LOGOS_KANA_MACRO_WAIT_MS>;
            tap-ms = <LOGOS_KANA_MACRO_TAP_MS>;
            bindings = <&kp LOGOS_KANA_FALLBACK_S &kp LOGOS_KANA_FALLBACK_SEMI>;
        };

        logos_kana_xo: logos_kana_xo {
            compatible = "zmk,behavior-macro";
            #binding-cells = <0>;
            wait-ms = <LOGOS_KANA_MACRO_WAIT_MS>;
            tap-ms = <LOGOS_KANA_MACRO_TAP_MS>;
            bindings = <&kp X &kp O>;
        };

        logos_kana_xo_pass: logos_kana_xo_pass {
            compatible = "zmk,behavior-macro";
            #binding-cells = <0>;
            wait-ms = <LOGOS_KANA_MACRO_WAIT_MS>;
            tap-ms = <LOGOS_KANA_MACRO_TAP_MS>;
            bindings = <&kp LOGOS_KANA_FALLBACK_L &kp LOGOS_KANA_FALLBACK_Z>;
        };

        logos_kana_pe: logos_kana_pe {
            compatible = "zmk,behavior-macro";
            #binding-cells = <0>;
            wait-ms = <LOGOS_KANA_MACRO_WAIT_MS>;
            tap-ms = <LOGOS_KANA_MACRO_TAP_MS>;
            bindings = <&kp P &kp E>;
        };

        logos_kana_pe_pass: logos_kana_pe_pass {
            compatible = "zmk,behavior-macro";
            #binding-cells = <0>;
            wait-ms = <LOGOS_KANA_MACRO_WAIT_MS>;
            tap-ms = <LOGOS_KANA_MACRO_TAP_MS>;
            bindings = <&kp LOGOS_KANA_FALLBACK_L &kp LOGOS_KANA_FALLBACK_X>;
        };

        logos_kana_bo: logos_kana_bo {
            compatible = "zmk,behavior-macro";
            #binding-cells = <0>;
            wait-ms = <LOGOS_KANA_MACRO_WAIT_MS>;
            tap-ms = <LOGOS_KANA_MACRO_TAP_MS>;
            bindings = <&kp B &kp O>;
        };

        logos_kana_bo_pass: logos_kana_bo_pass {
            compatible = "zmk,behavior-macro";
            #binding-cells = <0>;
            wait-ms = <LOGOS_KANA_MACRO_WAIT_MS>;
            tap-ms = <LOGOS_KANA_MACRO_TAP_MS>;
            bindings = <&kp LOGOS_KANA_FALLBACK_L &kp LOGOS_KANA_FALLBACK_C>;
        };

        logos_kana_he: logos_kana_he {
            compatible = "zmk,behavior-macro";
            #binding-cells = <0>;
            wait-ms = <LOGOS_KANA_MACRO_WAIT_MS>;
            tap-ms = <LOGOS_KANA_MACRO_TAP_MS>;
            bindings = <&kp H &kp E>;
        };

        logos_kana_he_pass: logos_kana_he_pass {
            compatible = "zmk,behavior-macro";
            #binding-cells = <0>;
            wait-ms = <LOGOS_KANA_MACRO_WAIT_MS>;
            tap-ms = <LOGOS_KANA_MACRO_TAP_MS>;
            bindings = <&kp LOGOS_KANA_FALLBACK_L &kp LOGOS_KANA_FALLBACK_V>;
        };

        logos_kana_xya: logos_kana_xya {
            compatible = "zmk,behavior-macro";
            #binding-cells = <0>;
            wait-ms = <LOGOS_KANA_MACRO_WAIT_MS>;
            tap-ms = <LOGOS_KANA_MACRO_TAP_MS>;
            bindings = <&kp X &kp Y &kp A>;
        };

        logos_kana_xya_pass: logos_kana_xya_pass {
            compatible = "zmk,behavior-macro";
            #binding-cells = <0>;
            wait-ms = <LOGOS_KANA_MACRO_WAIT_MS>;
            tap-ms = <LOGOS_KANA_MACRO_TAP_MS>;
            bindings = <&kp LOGOS_KANA_FALLBACK_L &kp LOGOS_KANA_FALLBACK_B>;
        };

        logos_kana_xyu: logos_kana_xyu {
            compatible = "zmk,behavior-macro";
            #binding-cells = <0>;
            wait-ms = <LOGOS_KANA_MACRO_WAIT_MS>;
            tap-ms = <LOGOS_KANA_MACRO_TAP_MS>;
            bindings = <&kp X &kp Y &kp U>;
        };

        logos_kana_xyu_pass: logos_kana_xyu_pass {
            compatible = "zmk,behavior-macro";
            #binding-cells = <0>;
            wait-ms = <LOGOS_KANA_MACRO_WAIT_MS>;
            tap-ms = <LOGOS_KANA_MACRO_TAP_MS>;
            bindings = <&kp LOGOS_KANA_FALLBACK_S &kp LOGOS_KANA_FALLBACK_N>;
        };

        logos_kana_mu: logos_kana_mu {
            compatible = "zmk,behavior-macro";
            #binding-cells = <0>;
            wait-ms = <LOGOS_KANA_MACRO_WAIT_MS>;
            tap-ms = <LOGOS_KANA_MACRO_TAP_MS>;
            bindings = <&kp M &kp U>;
        };

        logos_kana_mu_pass: logos_kana_mu_pass {
            compatible = "zmk,behavior-macro";
            #binding-cells = <0>;
            wait-ms = <LOGOS_KANA_MACRO_WAIT_MS>;
            tap-ms = <LOGOS_KANA_MACRO_TAP_MS>;
            bindings = <&kp LOGOS_KANA_FALLBACK_S &kp LOGOS_KANA_FALLBACK_M>;
        };

        logos_kana_zu: logos_kana_zu {
            compatible = "zmk,behavior-macro";
            #binding-cells = <0>;
            wait-ms = <LOGOS_KANA_MACRO_WAIT_MS>;
            tap-ms = <LOGOS_KANA_MACRO_TAP_MS>;
            bindings = <&kp Z &kp U>;
        };

        logos_kana_zu_pass: logos_kana_zu_pass {
            compatible = "zmk,behavior-macro";
            #binding-cells = <0>;
            wait-ms = <LOGOS_KANA_MACRO_WAIT_MS>;
            tap-ms = <LOGOS_KANA_MACRO_TAP_MS>;
            bindings = <&kp LOGOS_KANA_FALLBACK_S &kp LOGOS_KANA_FALLBACK_COMMA>;
        };

        logos_kana_thi: logos_kana_thi {
            compatible = "zmk,behavior-macro";
            #binding-cells = <0>;
            wait-ms = <LOGOS_KANA_MACRO_WAIT_MS>;
            tap-ms = <LOGOS_KANA_MACRO_TAP_MS>;
            bindings = <&kp T &kp H &kp I>;
        };

        logos_kana_thi_pass: logos_kana_thi_pass {
            compatible = "zmk,behavior-macro";
            #binding-cells = <0>;
            wait-ms = <LOGOS_KANA_MACRO_WAIT_MS>;
            tap-ms = <LOGOS_KANA_MACRO_TAP_MS>;
            bindings = <&kp LOGOS_KANA_FALLBACK_S &kp LOGOS_KANA_FALLBACK_DOT>;
        };

        logos_kana_xyo: logos_kana_xyo {
            compatible = "zmk,behavior-macro";
            #binding-cells = <0>;
            wait-ms = <LOGOS_KANA_MACRO_WAIT_MS>;
            tap-ms = <LOGOS_KANA_MACRO_TAP_MS>;
            bindings = <&kp X &kp Y &kp O>;
        };

        logos_kana_xyo_pass: logos_kana_xyo_pass {
            compatible = "zmk,behavior-macro";
            #binding-cells = <0>;
            wait-ms = <LOGOS_KANA_MACRO_WAIT_MS>;
            tap-ms = <LOGOS_KANA_MACRO_TAP_MS>;
            bindings = <&kp LOGOS_KANA_FALLBACK_S &kp LOGOS_KANA_FALLBACK_SLASH>;
        };

        logos_kana_sya: logos_kana_sya {
            compatible = "zmk,behavior-macro";
            #binding-cells = <0>;
            wait-ms = <LOGOS_KANA_MACRO_WAIT_MS>;
            tap-ms = <LOGOS_KANA_MACRO_TAP_MS>;
            bindings = <&kp S &kp Y &kp A>;
        };

        logos_kana_sya_pass: logos_kana_sya_pass {
            compatible = "zmk,behavior-macro";
            #binding-cells = <0>;
            wait-ms = <LOGOS_KANA_MACRO_WAIT_MS>;
            tap-ms = <LOGOS_KANA_MACRO_TAP_MS>;
            bindings = <&kp LOGOS_KANA_FALLBACK_E &kp LOGOS_KANA_FALLBACK_M>;
        };

        logos_kana_syu: logos_kana_syu {
            compatible = "zmk,behavior-macro";
            #binding-cells = <0>;
            wait-ms = <LOGOS_KANA_MACRO_WAIT_MS>;
            tap-ms = <LOGOS_KANA_MACRO_TAP_MS>;
            bindings = <&kp S &kp Y &kp U>;
        };

        logos_kana_syu_pass: logos_kana_syu_pass {
            compatible = "zmk,behavior-macro";
            #binding-cells = <0>;
            wait-ms = <LOGOS_KANA_MACRO_WAIT_MS>;
            tap-ms = <LOGOS_KANA_MACRO_TAP_MS>;
            bindings = <&kp LOGOS_KANA_FALLBACK_E &kp LOGOS_KANA_FALLBACK_U>;
        };

        logos_kana_syo: logos_kana_syo {
            compatible = "zmk,behavior-macro";
            #binding-cells = <0>;
            wait-ms = <LOGOS_KANA_MACRO_WAIT_MS>;
            tap-ms = <LOGOS_KANA_MACRO_TAP_MS>;
            bindings = <&kp S &kp Y &kp O>;
        };

        logos_kana_syo_pass: logos_kana_syo_pass {
            compatible = "zmk,behavior-macro";
            #binding-cells = <0>;
            wait-ms = <LOGOS_KANA_MACRO_WAIT_MS>;
            tap-ms = <LOGOS_KANA_MACRO_TAP_MS>;
            bindings = <&kp LOGOS_KANA_FALLBACK_E &kp LOGOS_KANA_FALLBACK_J>;
        };

        logos_kana_kya: logos_kana_kya {
            compatible = "zmk,behavior-macro";
            #binding-cells = <0>;
            wait-ms = <LOGOS_KANA_MACRO_WAIT_MS>;
            tap-ms = <LOGOS_KANA_MACRO_TAP_MS>;
            bindings = <&kp K &kp Y &kp A>;
        };

        logos_kana_kya_pass: logos_kana_kya_pass {
            compatible = "zmk,behavior-macro";
            #binding-cells = <0>;
            wait-ms = <LOGOS_KANA_MACRO_WAIT_MS>;
            tap-ms = <LOGOS_KANA_MACRO_TAP_MS>;
            bindings = <&kp LOGOS_KANA_FALLBACK_E &kp LOGOS_KANA_FALLBACK_COMMA>;
        };

        logos_kana_kyu: logos_kana_kyu {
            compatible = "zmk,behavior-macro";
            #binding-cells = <0>;
            wait-ms = <LOGOS_KANA_MACRO_WAIT_MS>;
            tap-ms = <LOGOS_KANA_MACRO_TAP_MS>;
            bindings = <&kp K &kp Y &kp U>;
        };

        logos_kana_kyu_pass: logos_kana_kyu_pass {
            compatible = "zmk,behavior-macro";
            #binding-cells = <0>;
            wait-ms = <LOGOS_KANA_MACRO_WAIT_MS>;
            tap-ms = <LOGOS_KANA_MACRO_TAP_MS>;
            bindings = <&kp LOGOS_KANA_FALLBACK_E &kp LOGOS_KANA_FALLBACK_O>;
        };

        logos_kana_kyo: logos_kana_kyo {
            compatible = "zmk,behavior-macro";
            #binding-cells = <0>;
            wait-ms = <LOGOS_KANA_MACRO_WAIT_MS>;
            tap-ms = <LOGOS_KANA_MACRO_TAP_MS>;
            bindings = <&kp K &kp Y &kp O>;
        };

        logos_kana_kyo_pass: logos_kana_kyo_pass {
            compatible = "zmk,behavior-macro";
            #binding-cells = <0>;
            wait-ms = <LOGOS_KANA_MACRO_WAIT_MS>;
            tap-ms = <LOGOS_KANA_MACRO_TAP_MS>;
            bindings = <&kp LOGOS_KANA_FALLBACK_E &kp LOGOS_KANA_FALLBACK_I>;
        };

        logos_kana_tya: logos_kana_tya {
            compatible = "zmk,behavior-macro";
            #binding-cells = <0>;
            wait-ms = <LOGOS_KANA_MACRO_WAIT_MS>;
            tap-ms = <LOGOS_KANA_MACRO_TAP_MS>;
            bindings = <&kp T &kp Y &kp A>;
        };

        logos_kana_tya_pass: logos_kana_tya_pass {
            compatible = "zmk,behavior-macro";
            #binding-cells = <0>;
            wait-ms = <LOGOS_KANA_MACRO_WAIT_MS>;
            tap-ms = <LOGOS_KANA_MACRO_TAP_MS>;
            bindings = <&kp LOGOS_KANA_FALLBACK_E &kp LOGOS_KANA_FALLBACK_N>;
        };

        logos_kana_tyu: logos_kana_tyu {
            compatible = "zmk,behavior-macro";
            #binding-cells = <0>;
            wait-ms = <LOGOS_KANA_MACRO_WAIT_MS>;
            tap-ms = <LOGOS_KANA_MACRO_TAP_MS>;
            bindings = <&kp T &kp Y &kp U>;
        };

        logos_kana_tyu_pass: logos_kana_tyu_pass {
            compatible = "zmk,behavior-macro";
            #binding-cells = <0>;
            wait-ms = <LOGOS_KANA_MACRO_WAIT_MS>;
            tap-ms = <LOGOS_KANA_MACRO_TAP_MS>;
            bindings = <&kp LOGOS_KANA_FALLBACK_E &kp LOGOS_KANA_FALLBACK_Y>;
        };

        logos_kana_tyo: logos_kana_tyo {
            compatible = "zmk,behavior-macro";
            #binding-cells = <0>;
            wait-ms = <LOGOS_KANA_MACRO_WAIT_MS>;
            tap-ms = <LOGOS_KANA_MACRO_TAP_MS>;
            bindings = <&kp T &kp Y &kp O>;
        };

        logos_kana_tyo_pass: logos_kana_tyo_pass {
            compatible = "zmk,behavior-macro";
            #binding-cells = <0>;
            wait-ms = <LOGOS_KANA_MACRO_WAIT_MS>;
            tap-ms = <LOGOS_KANA_MACRO_TAP_MS>;
            bindings = <&kp LOGOS_KANA_FALLBACK_E &kp LOGOS_KANA_FALLBACK_H>;
        };

        logos_kana_hya: logos_kana_hya {
            compatible = "zmk,behavior-macro";
            #binding-cells = <0>;
            wait-ms = <LOGOS_KANA_MACRO_WAIT_MS>;
            tap-ms = <LOGOS_KANA_MACRO_TAP_MS>;
            bindings = <&kp H &kp Y &kp A>;
        };

        logos_kana_hya_pass: logos_kana_hya_pass {
            compatible = "zmk,behavior-macro";
            #binding-cells = <0>;
            wait-ms = <LOGOS_KANA_MACRO_WAIT_MS>;
            tap-ms = <LOGOS_KANA_MACRO_TAP_MS>;
            bindings = <&kp LOGOS_KANA_FALLBACK_E &kp LOGOS_KANA_FALLBACK_SLASH>;
        };

        logos_kana_hyu: logos_kana_hyu {
            compatible = "zmk,behavior-macro";
            #binding-cells = <0>;
            wait-ms = <LOGOS_KANA_MACRO_WAIT_MS>;
            tap-ms = <LOGOS_KANA_MACRO_TAP_MS>;
            bindings = <&kp H &kp Y &kp U>;
        };

        logos_kana_hyu_pass: logos_kana_hyu_pass {
            compatible = "zmk,behavior-macro";
            #binding-cells = <0>;
            wait-ms = <LOGOS_KANA_MACRO_WAIT_MS>;
            tap-ms = <LOGOS_KANA_MACRO_TAP_MS>;
            bindings = <&kp LOGOS_KANA_FALLBACK_E &kp LOGOS_KANA_FALLBACK_P>;
        };

        logos_kana_hyo: logos_kana_hyo {
            compatible = "zmk,behavior-macro";
            #binding-cells = <0>;
            wait-ms = <LOGOS_KANA_MACRO_WAIT_MS>;
            tap-ms = <LOGOS_KANA_MACRO_TAP_MS>;
            bindings = <&kp H &kp Y &kp O>;
        };

        logos_kana_hyo_pass: logos_kana_hyo_pass {
            compatible = "zmk,behavior-macro";
            #binding-cells = <0>;
            wait-ms = <LOGOS_KANA_MACRO_WAIT_MS>;
            tap-ms = <LOGOS_KANA_MACRO_TAP_MS>;
            bindings = <&kp LOGOS_KANA_FALLBACK_E &kp LOGOS_KANA_FALLBACK_SEMI>;
        };

        logos_kana_ja: logos_kana_ja {
            compatible = "zmk,behavior-macro";
            #binding-cells = <0>;
            wait-ms = <LOGOS_KANA_MACRO_WAIT_MS>;
            tap-ms = <LOGOS_KANA_MACRO_TAP_MS>;
            bindings = <&kp J &kp A>;
        };

        logos_kana_ja_pass: logos_kana_ja_pass {
            compatible = "zmk,behavior-macro";
            #binding-cells = <0>;
            wait-ms = <LOGOS_KANA_MACRO_WAIT_MS>;
            tap-ms = <LOGOS_KANA_MACRO_TAP_MS>;
            bindings = <&kp LOGOS_KANA_FALLBACK_W &kp LOGOS_KANA_FALLBACK_M>;
        };

        logos_kana_ju: logos_kana_ju {
            compatible = "zmk,behavior-macro";
            #binding-cells = <0>;
            wait-ms = <LOGOS_KANA_MACRO_WAIT_MS>;
            tap-ms = <LOGOS_KANA_MACRO_TAP_MS>;
            bindings = <&kp J &kp U>;
        };

        logos_kana_ju_pass: logos_kana_ju_pass {
            compatible = "zmk,behavior-macro";
            #binding-cells = <0>;
            wait-ms = <LOGOS_KANA_MACRO_WAIT_MS>;
            tap-ms = <LOGOS_KANA_MACRO_TAP_MS>;
            bindings = <&kp LOGOS_KANA_FALLBACK_W &kp LOGOS_KANA_FALLBACK_U>;
        };

        logos_kana_jo: logos_kana_jo {
            compatible = "zmk,behavior-macro";
            #binding-cells = <0>;
            wait-ms = <LOGOS_KANA_MACRO_WAIT_MS>;
            tap-ms = <LOGOS_KANA_MACRO_TAP_MS>;
            bindings = <&kp J &kp O>;
        };

        logos_kana_jo_pass: logos_kana_jo_pass {
            compatible = "zmk,behavior-macro";
            #binding-cells = <0>;
            wait-ms = <LOGOS_KANA_MACRO_WAIT_MS>;
            tap-ms = <LOGOS_KANA_MACRO_TAP_MS>;
            bindings = <&kp LOGOS_KANA_FALLBACK_W &kp LOGOS_KANA_FALLBACK_J>;
        };

        logos_kana_gya: logos_kana_gya {
            compatible = "zmk,behavior-macro";
            #binding-cells = <0>;
            wait-ms = <LOGOS_KANA_MACRO_WAIT_MS>;
            tap-ms = <LOGOS_KANA_MACRO_TAP_MS>;
            bindings = <&kp G &kp Y &kp A>;
        };

        logos_kana_gya_pass: logos_kana_gya_pass {
            compatible = "zmk,behavior-macro";
            #binding-cells = <0>;
            wait-ms = <LOGOS_KANA_MACRO_WAIT_MS>;
            tap-ms = <LOGOS_KANA_MACRO_TAP_MS>;
            bindings = <&kp LOGOS_KANA_FALLBACK_W &kp LOGOS_KANA_FALLBACK_COMMA>;
        };

        logos_kana_gyu: logos_kana_gyu {
            compatible = "zmk,behavior-macro";
            #binding-cells = <0>;
            wait-ms = <LOGOS_KANA_MACRO_WAIT_MS>;
            tap-ms = <LOGOS_KANA_MACRO_TAP_MS>;
            bindings = <&kp G &kp Y &kp U>;
        };

        logos_kana_gyu_pass: logos_kana_gyu_pass {
            compatible = "zmk,behavior-macro";
            #binding-cells = <0>;
            wait-ms = <LOGOS_KANA_MACRO_WAIT_MS>;
            tap-ms = <LOGOS_KANA_MACRO_TAP_MS>;
            bindings = <&kp LOGOS_KANA_FALLBACK_W &kp LOGOS_KANA_FALLBACK_O>;
        };

        logos_kana_gyo: logos_kana_gyo {
            compatible = "zmk,behavior-macro";
            #binding-cells = <0>;
            wait-ms = <LOGOS_KANA_MACRO_WAIT_MS>;
            tap-ms = <LOGOS_KANA_MACRO_TAP_MS>;
            bindings = <&kp G &kp Y &kp O>;
        };

        logos_kana_gyo_pass: logos_kana_gyo_pass {
            compatible = "zmk,behavior-macro";
            #binding-cells = <0>;
            wait-ms = <LOGOS_KANA_MACRO_WAIT_MS>;
            tap-ms = <LOGOS_KANA_MACRO_TAP_MS>;
            bindings = <&kp LOGOS_KANA_FALLBACK_W &kp LOGOS_KANA_FALLBACK_I>;
        };

        logos_kana_nya: logos_kana_nya {
            compatible = "zmk,behavior-macro";
            #binding-cells = <0>;
            wait-ms = <LOGOS_KANA_MACRO_WAIT_MS>;
            tap-ms = <LOGOS_KANA_MACRO_TAP_MS>;
            bindings = <&kp N &kp Y &kp A>;
        };

        logos_kana_nya_pass: logos_kana_nya_pass {
            compatible = "zmk,behavior-macro";
            #binding-cells = <0>;
            wait-ms = <LOGOS_KANA_MACRO_WAIT_MS>;
            tap-ms = <LOGOS_KANA_MACRO_TAP_MS>;
            bindings = <&kp LOGOS_KANA_FALLBACK_W &kp LOGOS_KANA_FALLBACK_N>;
        };

        logos_kana_nyu: logos_kana_nyu {
            compatible = "zmk,behavior-macro";
            #binding-cells = <0>;
            wait-ms = <LOGOS_KANA_MACRO_WAIT_MS>;
            tap-ms = <LOGOS_KANA_MACRO_TAP_MS>;
            bindings = <&kp N &kp Y &kp U>;
        };

        logos_kana_nyu_pass: logos_kana_nyu_pass {
            compatible = "zmk,behavior-macro";
            #binding-cells = <0>;
            wait-ms = <LOGOS_KANA_MACRO_WAIT_MS>;
            tap-ms = <LOGOS_KANA_MACRO_TAP_MS>;
            bindings = <&kp LOGOS_KANA_FALLBACK_W &kp LOGOS_KANA_FALLBACK_Y>;
        };

        logos_kana_nyo: logos_kana_nyo {
            compatible = "zmk,behavior-macro";
            #binding-cells = <0>;
            wait-ms = <LOGOS_KANA_MACRO_WAIT_MS>;
            tap-ms = <LOGOS_KANA_MACRO_TAP_MS>;
            bindings = <&kp N &kp Y &kp O>;
        };

        logos_kana_nyo_pass: logos_kana_nyo_pass {
            compatible = "zmk,behavior-macro";
            #binding-cells = <0>;
            wait-ms = <LOGOS_KANA_MACRO_WAIT_MS>;
            tap-ms = <LOGOS_KANA_MACRO_TAP_MS>;
            bindings = <&kp LOGOS_KANA_FALLBACK_W &kp LOGOS_KANA_FALLBACK_H>;
        };

        logos_kana_bya: logos_kana_bya {
            compatible = "zmk,behavior-macro";
            #binding-cells = <0>;
            wait-ms = <LOGOS_KANA_MACRO_WAIT_MS>;
            tap-ms = <LOGOS_KANA_MACRO_TAP_MS>;
            bindings = <&kp B &kp Y &kp A>;
        };

        logos_kana_bya_pass: logos_kana_bya_pass {
            compatible = "zmk,behavior-macro";
            #binding-cells = <0>;
            wait-ms = <LOGOS_KANA_MACRO_WAIT_MS>;
            tap-ms = <LOGOS_KANA_MACRO_TAP_MS>;
            bindings = <&kp LOGOS_KANA_FALLBACK_W &kp LOGOS_KANA_FALLBACK_SLASH>;
        };

        logos_kana_byu: logos_kana_byu {
            compatible = "zmk,behavior-macro";
            #binding-cells = <0>;
            wait-ms = <LOGOS_KANA_MACRO_WAIT_MS>;
            tap-ms = <LOGOS_KANA_MACRO_TAP_MS>;
            bindings = <&kp B &kp Y &kp U>;
        };

        logos_kana_byu_pass: logos_kana_byu_pass {
            compatible = "zmk,behavior-macro";
            #binding-cells = <0>;
            wait-ms = <LOGOS_KANA_MACRO_WAIT_MS>;
            tap-ms = <LOGOS_KANA_MACRO_TAP_MS>;
            bindings = <&kp LOGOS_KANA_FALLBACK_W &kp LOGOS_KANA_FALLBACK_P>;
        };

        logos_kana_byo: logos_kana_byo {
            compatible = "zmk,behavior-macro";
            #binding-cells = <0>;
            wait-ms = <LOGOS_KANA_MACRO_WAIT_MS>;
            tap-ms = <LOGOS_KANA_MACRO_TAP_MS>;
            bindings = <&kp B &kp Y &kp O>;
        };

        logos_kana_byo_pass: logos_kana_byo_pass {
            compatible = "zmk,behavior-macro";
            #binding-cells = <0>;
            wait-ms = <LOGOS_KANA_MACRO_WAIT_MS>;
            tap-ms = <LOGOS_KANA_MACRO_TAP_MS>;
            bindings = <&kp LOGOS_KANA_FALLBACK_W &kp LOGOS_KANA_FALLBACK_SEMI>;
        };

        logos_kana_rya: logos_kana_rya {
            compatible = "zmk,behavior-macro";
            #binding-cells = <0>;
            wait-ms = <LOGOS_KANA_MACRO_WAIT_MS>;
            tap-ms = <LOGOS_KANA_MACRO_TAP_MS>;
            bindings = <&kp R &kp Y &kp A>;
        };

        logos_kana_rya_pass: logos_kana_rya_pass {
            compatible = "zmk,behavior-macro";
            #binding-cells = <0>;
            wait-ms = <LOGOS_KANA_MACRO_WAIT_MS>;
            tap-ms = <LOGOS_KANA_MACRO_TAP_MS>;
            bindings = <&kp LOGOS_KANA_FALLBACK_A &kp LOGOS_KANA_FALLBACK_M>;
        };

        logos_kana_ryu: logos_kana_ryu {
            compatible = "zmk,behavior-macro";
            #binding-cells = <0>;
            wait-ms = <LOGOS_KANA_MACRO_WAIT_MS>;
            tap-ms = <LOGOS_KANA_MACRO_TAP_MS>;
            bindings = <&kp R &kp Y &kp U>;
        };

        logos_kana_ryu_pass: logos_kana_ryu_pass {
            compatible = "zmk,behavior-macro";
            #binding-cells = <0>;
            wait-ms = <LOGOS_KANA_MACRO_WAIT_MS>;
            tap-ms = <LOGOS_KANA_MACRO_TAP_MS>;
            bindings = <&kp LOGOS_KANA_FALLBACK_A &kp LOGOS_KANA_FALLBACK_U>;
        };

        logos_kana_ryo: logos_kana_ryo {
            compatible = "zmk,behavior-macro";
            #binding-cells = <0>;
            wait-ms = <LOGOS_KANA_MACRO_WAIT_MS>;
            tap-ms = <LOGOS_KANA_MACRO_TAP_MS>;
            bindings = <&kp R &kp Y &kp O>;
        };

        logos_kana_ryo_pass: logos_kana_ryo_pass {
            compatible = "zmk,behavior-macro";
            #binding-cells = <0>;
            wait-ms = <LOGOS_KANA_MACRO_WAIT_MS>;
            tap-ms = <LOGOS_KANA_MACRO_TAP_MS>;
            bindings = <&kp LOGOS_KANA_FALLBACK_A &kp LOGOS_KANA_FALLBACK_J>;
        };

        logos_kana_mya: logos_kana_mya {
            compatible = "zmk,behavior-macro";
            #binding-cells = <0>;
            wait-ms = <LOGOS_KANA_MACRO_WAIT_MS>;
            tap-ms = <LOGOS_KANA_MACRO_TAP_MS>;
            bindings = <&kp M &kp Y &kp A>;
        };

        logos_kana_mya_pass: logos_kana_mya_pass {
            compatible = "zmk,behavior-macro";
            #binding-cells = <0>;
            wait-ms = <LOGOS_KANA_MACRO_WAIT_MS>;
            tap-ms = <LOGOS_KANA_MACRO_TAP_MS>;
            bindings = <&kp LOGOS_KANA_FALLBACK_A &kp LOGOS_KANA_FALLBACK_COMMA>;
        };

        logos_kana_myu: logos_kana_myu {
            compatible = "zmk,behavior-macro";
            #binding-cells = <0>;
            wait-ms = <LOGOS_KANA_MACRO_WAIT_MS>;
            tap-ms = <LOGOS_KANA_MACRO_TAP_MS>;
            bindings = <&kp M &kp Y &kp U>;
        };

        logos_kana_myu_pass: logos_kana_myu_pass {
            compatible = "zmk,behavior-macro";
            #binding-cells = <0>;
            wait-ms = <LOGOS_KANA_MACRO_WAIT_MS>;
            tap-ms = <LOGOS_KANA_MACRO_TAP_MS>;
            bindings = <&kp LOGOS_KANA_FALLBACK_A &kp LOGOS_KANA_FALLBACK_O>;
        };

        logos_kana_myo: logos_kana_myo {
            compatible = "zmk,behavior-macro";
            #binding-cells = <0>;
            wait-ms = <LOGOS_KANA_MACRO_WAIT_MS>;
            tap-ms = <LOGOS_KANA_MACRO_TAP_MS>;
            bindings = <&kp M &kp Y &kp O>;
        };

        logos_kana_myo_pass: logos_kana_myo_pass {
            compatible = "zmk,behavior-macro";
            #binding-cells = <0>;
            wait-ms = <LOGOS_KANA_MACRO_WAIT_MS>;
            tap-ms = <LOGOS_KANA_MACRO_TAP_MS>;
            bindings = <&kp LOGOS_KANA_FALLBACK_A &kp LOGOS_KANA_FALLBACK_I>;
        };

        logos_kana_vi: logos_kana_vi {
            compatible = "zmk,behavior-macro";
            #binding-cells = <0>;
            wait-ms = <LOGOS_KANA_MACRO_WAIT_MS>;
            tap-ms = <LOGOS_KANA_MACRO_TAP_MS>;
            bindings = <&kp V &kp I>;
        };

        logos_kana_vi_pass: logos_kana_vi_pass {
            compatible = "zmk,behavior-macro";
            #binding-cells = <0>;
            wait-ms = <LOGOS_KANA_MACRO_WAIT_MS>;
            tap-ms = <LOGOS_KANA_MACRO_TAP_MS>;
            bindings = <&kp LOGOS_KANA_FALLBACK_A &kp LOGOS_KANA_FALLBACK_N>;
        };

        logos_kana_va: logos_kana_va {
            compatible = "zmk,behavior-macro";
            #binding-cells = <0>;
            wait-ms = <LOGOS_KANA_MACRO_WAIT_MS>;
            tap-ms = <LOGOS_KANA_MACRO_TAP_MS>;
            bindings = <&kp V &kp A>;
        };

        logos_kana_va_pass: logos_kana_va_pass {
            compatible = "zmk,behavior-macro";
            #binding-cells = <0>;
            wait-ms = <LOGOS_KANA_MACRO_WAIT_MS>;
            tap-ms = <LOGOS_KANA_MACRO_TAP_MS>;
            bindings = <&kp LOGOS_KANA_FALLBACK_A &kp LOGOS_KANA_FALLBACK_Y>;
        };

        logos_kana_che: logos_kana_che {
            compatible = "zmk,behavior-macro";
            #binding-cells = <0>;
            wait-ms = <LOGOS_KANA_MACRO_WAIT_MS>;
            tap-ms = <LOGOS_KANA_MACRO_TAP_MS>;
            bindings = <&kp C &kp H &kp E>;
        };

        logos_kana_che_pass: logos_kana_che_pass {
            compatible = "zmk,behavior-macro";
            #binding-cells = <0>;
            wait-ms = <LOGOS_KANA_MACRO_WAIT_MS>;
            tap-ms = <LOGOS_KANA_MACRO_TAP_MS>;
            bindings = <&kp LOGOS_KANA_FALLBACK_A &kp LOGOS_KANA_FALLBACK_H>;
        };

        logos_kana_pya: logos_kana_pya {
            compatible = "zmk,behavior-macro";
            #binding-cells = <0>;
            wait-ms = <LOGOS_KANA_MACRO_WAIT_MS>;
            tap-ms = <LOGOS_KANA_MACRO_TAP_MS>;
            bindings = <&kp P &kp Y &kp A>;
        };

        logos_kana_pya_pass: logos_kana_pya_pass {
            compatible = "zmk,behavior-macro";
            #binding-cells = <0>;
            wait-ms = <LOGOS_KANA_MACRO_WAIT_MS>;
            tap-ms = <LOGOS_KANA_MACRO_TAP_MS>;
            bindings = <&kp LOGOS_KANA_FALLBACK_A &kp LOGOS_KANA_FALLBACK_SLASH>;
        };

        logos_kana_pyu: logos_kana_pyu {
            compatible = "zmk,behavior-macro";
            #binding-cells = <0>;
            wait-ms = <LOGOS_KANA_MACRO_WAIT_MS>;
            tap-ms = <LOGOS_KANA_MACRO_TAP_MS>;
            bindings = <&kp P &kp Y &kp U>;
        };

        logos_kana_pyu_pass: logos_kana_pyu_pass {
            compatible = "zmk,behavior-macro";
            #binding-cells = <0>;
            wait-ms = <LOGOS_KANA_MACRO_WAIT_MS>;
            tap-ms = <LOGOS_KANA_MACRO_TAP_MS>;
            bindings = <&kp LOGOS_KANA_FALLBACK_A &kp LOGOS_KANA_FALLBACK_P>;
        };

        logos_kana_pyo: logos_kana_pyo {
            compatible = "zmk,behavior-macro";
            #binding-cells = <0>;
            wait-ms = <LOGOS_KANA_MACRO_WAIT_MS>;
            tap-ms = <LOGOS_KANA_MACRO_TAP_MS>;
            bindings = <&kp P &kp Y &kp O>;
        };

        logos_kana_pyo_pass: logos_kana_pyo_pass {
            compatible = "zmk,behavior-macro";
            #binding-cells = <0>;
            wait-ms = <LOGOS_KANA_MACRO_WAIT_MS>;
            tap-ms = <LOGOS_KANA_MACRO_TAP_MS>;
            bindings = <&kp LOGOS_KANA_FALLBACK_A &kp LOGOS_KANA_FALLBACK_SEMI>;
        };

        logos_kana_fi: logos_kana_fi {
            compatible = "zmk,behavior-macro";
            #binding-cells = <0>;
            wait-ms = <LOGOS_KANA_MACRO_WAIT_MS>;
            tap-ms = <LOGOS_KANA_MACRO_TAP_MS>;
            bindings = <&kp F &kp I>;
        };

        logos_kana_fi_pass: logos_kana_fi_pass {
            compatible = "zmk,behavior-macro";
            #binding-cells = <0>;
            wait-ms = <LOGOS_KANA_MACRO_WAIT_MS>;
            tap-ms = <LOGOS_KANA_MACRO_TAP_MS>;
            bindings = <&kp LOGOS_KANA_FALLBACK_Z &kp LOGOS_KANA_FALLBACK_U>;
        };

        logos_kana_fa: logos_kana_fa {
            compatible = "zmk,behavior-macro";
            #binding-cells = <0>;
            wait-ms = <LOGOS_KANA_MACRO_WAIT_MS>;
            tap-ms = <LOGOS_KANA_MACRO_TAP_MS>;
            bindings = <&kp F &kp A>;
        };

        logos_kana_fa_pass: logos_kana_fa_pass {
            compatible = "zmk,behavior-macro";
            #binding-cells = <0>;
            wait-ms = <LOGOS_KANA_MACRO_WAIT_MS>;
            tap-ms = <LOGOS_KANA_MACRO_TAP_MS>;
            bindings = <&kp LOGOS_KANA_FALLBACK_Z &kp LOGOS_KANA_FALLBACK_J>;
        };

        logos_kana_fo: logos_kana_fo {
            compatible = "zmk,behavior-macro";
            #binding-cells = <0>;
            wait-ms = <LOGOS_KANA_MACRO_WAIT_MS>;
            tap-ms = <LOGOS_KANA_MACRO_TAP_MS>;
            bindings = <&kp F &kp O>;
        };

        logos_kana_fo_pass: logos_kana_fo_pass {
            compatible = "zmk,behavior-macro";
            #binding-cells = <0>;
            wait-ms = <LOGOS_KANA_MACRO_WAIT_MS>;
            tap-ms = <LOGOS_KANA_MACRO_TAP_MS>;
            bindings = <&kp LOGOS_KANA_FALLBACK_Z &kp LOGOS_KANA_FALLBACK_M>;
        };

        logos_kana_she: logos_kana_she {
            compatible = "zmk,behavior-macro";
            #binding-cells = <0>;
            wait-ms = <LOGOS_KANA_MACRO_WAIT_MS>;
            tap-ms = <LOGOS_KANA_MACRO_TAP_MS>;
            bindings = <&kp S &kp H &kp E>;
        };

        logos_kana_she_pass: logos_kana_she_pass {
            compatible = "zmk,behavior-macro";
            #binding-cells = <0>;
            wait-ms = <LOGOS_KANA_MACRO_WAIT_MS>;
            tap-ms = <LOGOS_KANA_MACRO_TAP_MS>;
            bindings = <&kp LOGOS_KANA_FALLBACK_Z &kp LOGOS_KANA_FALLBACK_I>;
        };

        logos_kana_je: logos_kana_je {
            compatible = "zmk,behavior-macro";
            #binding-cells = <0>;
            wait-ms = <LOGOS_KANA_MACRO_WAIT_MS>;
            tap-ms = <LOGOS_KANA_MACRO_TAP_MS>;
            bindings = <&kp J &kp E>;
        };

        logos_kana_je_pass: logos_kana_je_pass {
            compatible = "zmk,behavior-macro";
            #binding-cells = <0>;
            wait-ms = <LOGOS_KANA_MACRO_WAIT_MS>;
            tap-ms = <LOGOS_KANA_MACRO_TAP_MS>;
            bindings = <&kp LOGOS_KANA_FALLBACK_Z &kp LOGOS_KANA_FALLBACK_COMMA>;
        };

        logos_kana_twu: logos_kana_twu {
            compatible = "zmk,behavior-macro";
            #binding-cells = <0>;
            wait-ms = <LOGOS_KANA_MACRO_WAIT_MS>;
            tap-ms = <LOGOS_KANA_MACRO_TAP_MS>;
            bindings = <&kp T &kp W &kp U>;
        };

        logos_kana_twu_pass: logos_kana_twu_pass {
            compatible = "zmk,behavior-macro";
            #binding-cells = <0>;
            wait-ms = <LOGOS_KANA_MACRO_WAIT_MS>;
            tap-ms = <LOGOS_KANA_MACRO_TAP_MS>;
            bindings = <&kp LOGOS_KANA_FALLBACK_Z &kp LOGOS_KANA_FALLBACK_O>;
        };

        logos_kana_dwu: logos_kana_dwu {
            compatible = "zmk,behavior-macro";
            #binding-cells = <0>;
            wait-ms = <LOGOS_KANA_MACRO_WAIT_MS>;
            tap-ms = <LOGOS_KANA_MACRO_TAP_MS>;
            bindings = <&kp D &kp W &kp U>;
        };

        logos_kana_dwu_pass: logos_kana_dwu_pass {
            compatible = "zmk,behavior-macro";
            #binding-cells = <0>;
            wait-ms = <LOGOS_KANA_MACRO_WAIT_MS>;
            tap-ms = <LOGOS_KANA_MACRO_TAP_MS>;
            bindings = <&kp LOGOS_KANA_FALLBACK_Z &kp LOGOS_KANA_FALLBACK_DOT>;
        };

        logos_kana_wi: logos_kana_wi {
            compatible = "zmk,behavior-macro";
            #binding-cells = <0>;
            wait-ms = <LOGOS_KANA_MACRO_WAIT_MS>;
            tap-ms = <LOGOS_KANA_MACRO_TAP_MS>;
            bindings = <&kp W &kp I>;
        };

        logos_kana_wi_pass: logos_kana_wi_pass {
            compatible = "zmk,behavior-macro";
            #binding-cells = <0>;
            wait-ms = <LOGOS_KANA_MACRO_WAIT_MS>;
            tap-ms = <LOGOS_KANA_MACRO_TAP_MS>;
            bindings = <&kp LOGOS_KANA_FALLBACK_Z &kp LOGOS_KANA_FALLBACK_P>;
        };

        logos_kana_we: logos_kana_we {
            compatible = "zmk,behavior-macro";
            #binding-cells = <0>;
            wait-ms = <LOGOS_KANA_MACRO_WAIT_MS>;
            tap-ms = <LOGOS_KANA_MACRO_TAP_MS>;
            bindings = <&kp W &kp E>;
        };

        logos_kana_we_pass: logos_kana_we_pass {
            compatible = "zmk,behavior-macro";
            #binding-cells = <0>;
            wait-ms = <LOGOS_KANA_MACRO_WAIT_MS>;
            tap-ms = <LOGOS_KANA_MACRO_TAP_MS>;
            bindings = <&kp LOGOS_KANA_FALLBACK_Z &kp LOGOS_KANA_FALLBACK_SEMI>;
        };

        logos_kana_who: logos_kana_who {
            compatible = "zmk,behavior-macro";
            #binding-cells = <0>;
            wait-ms = <LOGOS_KANA_MACRO_WAIT_MS>;
            tap-ms = <LOGOS_KANA_MACRO_TAP_MS>;
            bindings = <&kp W &kp H &kp O>;
        };

        logos_kana_who_pass: logos_kana_who_pass {
            compatible = "zmk,behavior-macro";
            #binding-cells = <0>;
            wait-ms = <LOGOS_KANA_MACRO_WAIT_MS>;
            tap-ms = <LOGOS_KANA_MACRO_TAP_MS>;
            bindings = <&kp LOGOS_KANA_FALLBACK_Z &kp LOGOS_KANA_FALLBACK_SLASH>;
        };

        logos_kana_ve: logos_kana_ve {
            compatible = "zmk,behavior-macro";
            #binding-cells = <0>;
            wait-ms = <LOGOS_KANA_MACRO_WAIT_MS>;
            tap-ms = <LOGOS_KANA_MACRO_TAP_MS>;
            bindings = <&kp V &kp E>;
        };

        logos_kana_ve_pass: logos_kana_ve_pass {
            compatible = "zmk,behavior-macro";
            #binding-cells = <0>;
            wait-ms = <LOGOS_KANA_MACRO_WAIT_MS>;
            tap-ms = <LOGOS_KANA_MACRO_TAP_MS>;
            bindings = <&kp LOGOS_KANA_FALLBACK_Z &kp LOGOS_KANA_FALLBACK_Y>;
        };

        logos_kana_fe: logos_kana_fe {
            compatible = "zmk,behavior-macro";
            #binding-cells = <0>;
            wait-ms = <LOGOS_KANA_MACRO_WAIT_MS>;
            tap-ms = <LOGOS_KANA_MACRO_TAP_MS>;
            bindings = <&kp F &kp E>;
        };

        logos_kana_fe_pass: logos_kana_fe_pass {
            compatible = "zmk,behavior-macro";
            #binding-cells = <0>;
            wait-ms = <LOGOS_KANA_MACRO_WAIT_MS>;
            tap-ms = <LOGOS_KANA_MACRO_TAP_MS>;
            bindings = <&kp LOGOS_KANA_FALLBACK_Z &kp LOGOS_KANA_FALLBACK_H>;
        };

        logos_kana_vo: logos_kana_vo {
            compatible = "zmk,behavior-macro";
            #binding-cells = <0>;
            wait-ms = <LOGOS_KANA_MACRO_WAIT_MS>;
            tap-ms = <LOGOS_KANA_MACRO_TAP_MS>;
            bindings = <&kp V &kp O>;
        };

        logos_kana_vo_pass: logos_kana_vo_pass {
            compatible = "zmk,behavior-macro";
            #binding-cells = <0>;
            wait-ms = <LOGOS_KANA_MACRO_WAIT_MS>;
            tap-ms = <LOGOS_KANA_MACRO_TAP_MS>;
            bindings = <&kp LOGOS_KANA_FALLBACK_Z &kp LOGOS_KANA_FALLBACK_N>;
        };

    };

    combos {
        compatible = "zmk,combos";

        combo_logos_kana_di {
            timeout-ms = <LOGOS_KANA_COMBO_TIMEOUT_MS>;
            key-positions = <LOGOS_KANA_POS_K LOGOS_KANA_POS_Q>;
            layers = <LOGOS_KANA_LAYER>;
            bindings = <&logos_kana_di_combo>;
        };

        combo_logos_kana_ge {
            timeout-ms = <LOGOS_KANA_COMBO_TIMEOUT_MS>;
            key-positions = <LOGOS_KANA_POS_K LOGOS_KANA_POS_W>;
            layers = <LOGOS_KANA_LAYER>;
            bindings = <&logos_kana_ge_combo>;
        };

        combo_logos_kana_ho {
            timeout-ms = <LOGOS_KANA_COMBO_TIMEOUT_MS>;
            key-positions = <LOGOS_KANA_POS_K LOGOS_KANA_POS_E>;
            layers = <LOGOS_KANA_LAYER>;
            bindings = <&logos_kana_ho_combo>;
        };

        combo_logos_kana_gi {
            timeout-ms = <LOGOS_KANA_COMBO_TIMEOUT_MS>;
            key-positions = <LOGOS_KANA_POS_K LOGOS_KANA_POS_R>;
            layers = <LOGOS_KANA_LAYER>;
            bindings = <&logos_kana_gi_combo>;
        };

        combo_logos_kana_ze {
            timeout-ms = <LOGOS_KANA_COMBO_TIMEOUT_MS>;
            key-positions = <LOGOS_KANA_POS_K LOGOS_KANA_POS_T>;
            layers = <LOGOS_KANA_LAYER>;
            bindings = <&logos_kana_ze_combo>;
        };

        combo_logos_kana_du {
            timeout-ms = <LOGOS_KANA_COMBO_TIMEOUT_MS>;
            key-positions = <LOGOS_KANA_POS_D LOGOS_KANA_POS_Y>;
            layers = <LOGOS_KANA_LAYER>;
            bindings = <&logos_kana_du_combo>;
        };

        combo_logos_kana_yu {
            timeout-ms = <LOGOS_KANA_COMBO_TIMEOUT_MS>;
            key-positions = <LOGOS_KANA_POS_D LOGOS_KANA_POS_U>;
            layers = <LOGOS_KANA_LAYER>;
            bindings = <&logos_kana_yu_combo>;
        };

        combo_logos_kana_hu {
            timeout-ms = <LOGOS_KANA_COMBO_TIMEOUT_MS>;
            key-positions = <LOGOS_KANA_POS_D LOGOS_KANA_POS_I>;
            layers = <LOGOS_KANA_LAYER>;
            bindings = <&logos_kana_hu_combo>;
        };

        combo_logos_kana_bi {
            timeout-ms = <LOGOS_KANA_COMBO_TIMEOUT_MS>;
            key-positions = <LOGOS_KANA_POS_D LOGOS_KANA_POS_O>;
            layers = <LOGOS_KANA_LAYER>;
            bindings = <&logos_kana_bi_combo>;
        };

        combo_logos_kana_vu {
            timeout-ms = <LOGOS_KANA_COMBO_TIMEOUT_MS>;
            key-positions = <LOGOS_KANA_POS_D LOGOS_KANA_POS_P>;
            layers = <LOGOS_KANA_LAYER>;
            bindings = <&logos_kana_vu_combo>;
        };

        combo_logos_kana_ke {
            timeout-ms = <LOGOS_KANA_COMBO_TIMEOUT_MS>;
            key-positions = <LOGOS_KANA_POS_K LOGOS_KANA_POS_A>;
            layers = <LOGOS_KANA_LAYER>;
            bindings = <&logos_kana_ke_combo>;
        };

        combo_logos_kana_na {
            timeout-ms = <LOGOS_KANA_COMBO_TIMEOUT_MS>;
            key-positions = <LOGOS_KANA_POS_K LOGOS_KANA_POS_S>;
            layers = <LOGOS_KANA_LAYER>;
            bindings = <&logos_kana_na_combo>;
        };

        combo_logos_kana_ko {
            timeout-ms = <LOGOS_KANA_COMBO_TIMEOUT_MS>;
            key-positions = <LOGOS_KANA_POS_K LOGOS_KANA_POS_D>;
            layers = <LOGOS_KANA_LAYER>;
            bindings = <&logos_kana_ko_combo>;
        };

        combo_logos_kana_period {
            timeout-ms = <LOGOS_KANA_COMBO_TIMEOUT_MS>;
            key-positions = <LOGOS_KANA_POS_K LOGOS_KANA_POS_F>;
            layers = <LOGOS_KANA_LAYER>;
            bindings = <&logos_kana_period_combo>;
        };

        combo_logos_kana_zi {
            timeout-ms = <LOGOS_KANA_COMBO_TIMEOUT_MS>;
            key-positions = <LOGOS_KANA_POS_K LOGOS_KANA_POS_G>;
            layers = <LOGOS_KANA_LAYER>;
            bindings = <&logos_kana_zi_combo>;
        };

        combo_logos_kana_so {
            timeout-ms = <LOGOS_KANA_COMBO_TIMEOUT_MS>;
            key-positions = <LOGOS_KANA_POS_D LOGOS_KANA_POS_H>;
            layers = <LOGOS_KANA_LAYER>;
            bindings = <&logos_kana_so_combo>;
        };

        combo_logos_kana_o {
            timeout-ms = <LOGOS_KANA_COMBO_TIMEOUT_MS>;
            key-positions = <LOGOS_KANA_POS_D LOGOS_KANA_POS_J>;
            layers = <LOGOS_KANA_LAYER>;
            bindings = <&logos_kana_o_combo>;
        };

        combo_logos_kana_a {
            timeout-ms = <LOGOS_KANA_COMBO_TIMEOUT_MS>;
            key-positions = <LOGOS_KANA_POS_D LOGOS_KANA_POS_SEMI>;
            layers = <LOGOS_KANA_LAYER>;
            bindings = <&logos_kana_a_combo>;
        };

        combo_logos_kana_pi {
            timeout-ms = <LOGOS_KANA_COMBO_TIMEOUT_MS>;
            key-positions = <LOGOS_KANA_POS_K LOGOS_KANA_POS_Z>;
            layers = <LOGOS_KANA_LAYER>;
            bindings = <&logos_kana_pi_combo>;
        };

        combo_logos_kana_po {
            timeout-ms = <LOGOS_KANA_COMBO_TIMEOUT_MS>;
            key-positions = <LOGOS_KANA_POS_K LOGOS_KANA_POS_X>;
            layers = <LOGOS_KANA_LAYER>;
            bindings = <&logos_kana_po_combo>;
        };

        combo_logos_kana_ne {
            timeout-ms = <LOGOS_KANA_COMBO_TIMEOUT_MS>;
            key-positions = <LOGOS_KANA_POS_K LOGOS_KANA_POS_C>;
            layers = <LOGOS_KANA_LAYER>;
            bindings = <&logos_kana_ne_combo>;
        };

        combo_logos_kana_ba {
            timeout-ms = <LOGOS_KANA_COMBO_TIMEOUT_MS>;
            key-positions = <LOGOS_KANA_POS_K LOGOS_KANA_POS_V>;
            layers = <LOGOS_KANA_LAYER>;
            bindings = <&logos_kana_ba_combo>;
        };

        combo_logos_kana_pa {
            timeout-ms = <LOGOS_KANA_COMBO_TIMEOUT_MS>;
            key-positions = <LOGOS_KANA_POS_K LOGOS_KANA_POS_B>;
            layers = <LOGOS_KANA_LAYER>;
            bindings = <&logos_kana_pa_combo>;
        };

        combo_logos_kana_nu {
            timeout-ms = <LOGOS_KANA_COMBO_TIMEOUT_MS>;
            key-positions = <LOGOS_KANA_POS_D LOGOS_KANA_POS_N>;
            layers = <LOGOS_KANA_LAYER>;
            bindings = <&logos_kana_nu_combo>;
        };

        combo_logos_kana_mi {
            timeout-ms = <LOGOS_KANA_COMBO_TIMEOUT_MS>;
            key-positions = <LOGOS_KANA_POS_D LOGOS_KANA_POS_M>;
            layers = <LOGOS_KANA_LAYER>;
            bindings = <&logos_kana_mi_combo>;
        };

        combo_logos_kana_gu {
            timeout-ms = <LOGOS_KANA_COMBO_TIMEOUT_MS>;
            key-positions = <LOGOS_KANA_POS_D LOGOS_KANA_POS_COMMA>;
            layers = <LOGOS_KANA_LAYER>;
            bindings = <&logos_kana_gu_combo>;
        };

        combo_logos_kana_dhi {
            timeout-ms = <LOGOS_KANA_COMBO_TIMEOUT_MS>;
            key-positions = <LOGOS_KANA_POS_D LOGOS_KANA_POS_DOT>;
            layers = <LOGOS_KANA_LAYER>;
            bindings = <&logos_kana_dhi_combo>;
        };

        combo_logos_kana_pu {
            timeout-ms = <LOGOS_KANA_COMBO_TIMEOUT_MS>;
            key-positions = <LOGOS_KANA_POS_D LOGOS_KANA_POS_SLASH>;
            layers = <LOGOS_KANA_LAYER>;
            bindings = <&logos_kana_pu_combo>;
        };

        combo_logos_kana_xa {
            timeout-ms = <LOGOS_KANA_COMBO_TIMEOUT_MS>;
            key-positions = <LOGOS_KANA_POS_L LOGOS_KANA_POS_Q>;
            layers = <LOGOS_KANA_LAYER>;
            bindings = <&logos_kana_xa_combo>;
        };

        combo_logos_kana_me {
            timeout-ms = <LOGOS_KANA_COMBO_TIMEOUT_MS>;
            key-positions = <LOGOS_KANA_POS_L LOGOS_KANA_POS_W>;
            layers = <LOGOS_KANA_LAYER>;
            bindings = <&logos_kana_me_combo>;
        };

        combo_logos_kana_bu {
            timeout-ms = <LOGOS_KANA_COMBO_TIMEOUT_MS>;
            key-positions = <LOGOS_KANA_POS_L LOGOS_KANA_POS_E>;
            layers = <LOGOS_KANA_LAYER>;
            bindings = <&logos_kana_bu_combo>;
        };

        combo_logos_kana_za {
            timeout-ms = <LOGOS_KANA_COMBO_TIMEOUT_MS>;
            key-positions = <LOGOS_KANA_POS_L LOGOS_KANA_POS_R>;
            layers = <LOGOS_KANA_LAYER>;
            bindings = <&logos_kana_za_combo>;
        };

        combo_logos_kana_xi {
            timeout-ms = <LOGOS_KANA_COMBO_TIMEOUT_MS>;
            key-positions = <LOGOS_KANA_POS_L LOGOS_KANA_POS_T>;
            layers = <LOGOS_KANA_LAYER>;
            bindings = <&logos_kana_xi_combo>;
        };

        combo_logos_kana_xu {
            timeout-ms = <LOGOS_KANA_COMBO_TIMEOUT_MS>;
            key-positions = <LOGOS_KANA_POS_S LOGOS_KANA_POS_Y>;
            layers = <LOGOS_KANA_LAYER>;
            bindings = <&logos_kana_xu_combo>;
        };

        combo_logos_kana_zo {
            timeout-ms = <LOGOS_KANA_COMBO_TIMEOUT_MS>;
            key-positions = <LOGOS_KANA_POS_S LOGOS_KANA_POS_U>;
            layers = <LOGOS_KANA_LAYER>;
            bindings = <&logos_kana_zo_combo>;
        };

        combo_logos_kana_go {
            timeout-ms = <LOGOS_KANA_COMBO_TIMEOUT_MS>;
            key-positions = <LOGOS_KANA_POS_S LOGOS_KANA_POS_I>;
            layers = <LOGOS_KANA_LAYER>;
            bindings = <&logos_kana_go_combo>;
        };

        combo_logos_kana_be {
            timeout-ms = <LOGOS_KANA_COMBO_TIMEOUT_MS>;
            key-positions = <LOGOS_KANA_POS_S LOGOS_KANA_POS_O>;
            layers = <LOGOS_KANA_LAYER>;
            bindings = <&logos_kana_be_combo>;
        };

        combo_logos_kana_xe {
            timeout-ms = <LOGOS_KANA_COMBO_TIMEOUT_MS>;
            key-positions = <LOGOS_KANA_POS_S LOGOS_KANA_POS_P>;
            layers = <LOGOS_KANA_LAYER>;
            bindings = <&logos_kana_xe_combo>;
        };

        combo_logos_kana_ki {
            timeout-ms = <LOGOS_KANA_COMBO_TIMEOUT_MS>;
            key-positions = <LOGOS_KANA_POS_L LOGOS_KANA_POS_A>;
            layers = <LOGOS_KANA_LAYER>;
            bindings = <&logos_kana_ki_combo>;
        };

        combo_logos_kana_ri {
            timeout-ms = <LOGOS_KANA_COMBO_TIMEOUT_MS>;
            key-positions = <LOGOS_KANA_POS_L LOGOS_KANA_POS_S>;
            layers = <LOGOS_KANA_LAYER>;
            bindings = <&logos_kana_ri_combo>;
        };

        combo_logos_kana_su {
            timeout-ms = <LOGOS_KANA_COMBO_TIMEOUT_MS>;
            key-positions = <LOGOS_KANA_POS_L LOGOS_KANA_POS_D>;
            layers = <LOGOS_KANA_LAYER>;
            bindings = <&logos_kana_su_combo>;
        };

        combo_logos_kana_de {
            timeout-ms = <LOGOS_KANA_COMBO_TIMEOUT_MS>;
            key-positions = <LOGOS_KANA_POS_L LOGOS_KANA_POS_F>;
            layers = <LOGOS_KANA_LAYER>;
            bindings = <&logos_kana_de_combo>;
        };

        combo_logos_kana_ya {
            timeout-ms = <LOGOS_KANA_COMBO_TIMEOUT_MS>;
            key-positions = <LOGOS_KANA_POS_L LOGOS_KANA_POS_G>;
            layers = <LOGOS_KANA_LAYER>;
            bindings = <&logos_kana_ya_combo>;
        };

        combo_logos_kana_ro {
            timeout-ms = <LOGOS_KANA_COMBO_TIMEOUT_MS>;
            key-positions = <LOGOS_KANA_POS_S LOGOS_KANA_POS_H>;
            layers = <LOGOS_KANA_LAYER>;
            bindings = <&logos_kana_ro_combo>;
        };

        combo_logos_kana_ma {
            timeout-ms = <LOGOS_KANA_COMBO_TIMEOUT_MS>;
            key-positions = <LOGOS_KANA_POS_S LOGOS_KANA_POS_J>;
            layers = <LOGOS_KANA_LAYER>;
            bindings = <&logos_kana_ma_combo>;
        };

        combo_logos_kana_mo {
            timeout-ms = <LOGOS_KANA_COMBO_TIMEOUT_MS>;
            key-positions = <LOGOS_KANA_POS_S LOGOS_KANA_POS_SEMI>;
            layers = <LOGOS_KANA_LAYER>;
            bindings = <&logos_kana_mo_combo>;
        };

        combo_logos_kana_xo {
            timeout-ms = <LOGOS_KANA_COMBO_TIMEOUT_MS>;
            key-positions = <LOGOS_KANA_POS_L LOGOS_KANA_POS_Z>;
            layers = <LOGOS_KANA_LAYER>;
            bindings = <&logos_kana_xo_combo>;
        };

        combo_logos_kana_pe {
            timeout-ms = <LOGOS_KANA_COMBO_TIMEOUT_MS>;
            key-positions = <LOGOS_KANA_POS_L LOGOS_KANA_POS_X>;
            layers = <LOGOS_KANA_LAYER>;
            bindings = <&logos_kana_pe_combo>;
        };

        combo_logos_kana_bo {
            timeout-ms = <LOGOS_KANA_COMBO_TIMEOUT_MS>;
            key-positions = <LOGOS_KANA_POS_L LOGOS_KANA_POS_C>;
            layers = <LOGOS_KANA_LAYER>;
            bindings = <&logos_kana_bo_combo>;
        };

        combo_logos_kana_he {
            timeout-ms = <LOGOS_KANA_COMBO_TIMEOUT_MS>;
            key-positions = <LOGOS_KANA_POS_L LOGOS_KANA_POS_V>;
            layers = <LOGOS_KANA_LAYER>;
            bindings = <&logos_kana_he_combo>;
        };

        combo_logos_kana_xya {
            timeout-ms = <LOGOS_KANA_COMBO_TIMEOUT_MS>;
            key-positions = <LOGOS_KANA_POS_L LOGOS_KANA_POS_B>;
            layers = <LOGOS_KANA_LAYER>;
            bindings = <&logos_kana_xya_combo>;
        };

        combo_logos_kana_xyu {
            timeout-ms = <LOGOS_KANA_COMBO_TIMEOUT_MS>;
            key-positions = <LOGOS_KANA_POS_S LOGOS_KANA_POS_N>;
            layers = <LOGOS_KANA_LAYER>;
            bindings = <&logos_kana_xyu_combo>;
        };

        combo_logos_kana_mu {
            timeout-ms = <LOGOS_KANA_COMBO_TIMEOUT_MS>;
            key-positions = <LOGOS_KANA_POS_S LOGOS_KANA_POS_M>;
            layers = <LOGOS_KANA_LAYER>;
            bindings = <&logos_kana_mu_combo>;
        };

        combo_logos_kana_zu {
            timeout-ms = <LOGOS_KANA_COMBO_TIMEOUT_MS>;
            key-positions = <LOGOS_KANA_POS_S LOGOS_KANA_POS_COMMA>;
            layers = <LOGOS_KANA_LAYER>;
            bindings = <&logos_kana_zu_combo>;
        };

        combo_logos_kana_thi {
            timeout-ms = <LOGOS_KANA_COMBO_TIMEOUT_MS>;
            key-positions = <LOGOS_KANA_POS_S LOGOS_KANA_POS_DOT>;
            layers = <LOGOS_KANA_LAYER>;
            bindings = <&logos_kana_thi_combo>;
        };

        combo_logos_kana_xyo {
            timeout-ms = <LOGOS_KANA_COMBO_TIMEOUT_MS>;
            key-positions = <LOGOS_KANA_POS_S LOGOS_KANA_POS_SLASH>;
            layers = <LOGOS_KANA_LAYER>;
            bindings = <&logos_kana_xyo_combo>;
        };

        combo_logos_kana_sya {
            timeout-ms = <LOGOS_KANA_COMBO_TIMEOUT_MS>;
            key-positions = <LOGOS_KANA_POS_E LOGOS_KANA_POS_M>;
            layers = <LOGOS_KANA_LAYER>;
            bindings = <&logos_kana_sya_combo>;
        };

        combo_logos_kana_syu {
            timeout-ms = <LOGOS_KANA_COMBO_TIMEOUT_MS>;
            key-positions = <LOGOS_KANA_POS_E LOGOS_KANA_POS_U>;
            layers = <LOGOS_KANA_LAYER>;
            bindings = <&logos_kana_syu_combo>;
        };

        combo_logos_kana_syo {
            timeout-ms = <LOGOS_KANA_COMBO_TIMEOUT_MS>;
            key-positions = <LOGOS_KANA_POS_E LOGOS_KANA_POS_J>;
            layers = <LOGOS_KANA_LAYER>;
            bindings = <&logos_kana_syo_combo>;
        };

        combo_logos_kana_kya {
            timeout-ms = <LOGOS_KANA_COMBO_TIMEOUT_MS>;
            key-positions = <LOGOS_KANA_POS_E LOGOS_KANA_POS_COMMA>;
            layers = <LOGOS_KANA_LAYER>;
            bindings = <&logos_kana_kya_combo>;
        };

        combo_logos_kana_kyu {
            timeout-ms = <LOGOS_KANA_COMBO_TIMEOUT_MS>;
            key-positions = <LOGOS_KANA_POS_E LOGOS_KANA_POS_O>;
            layers = <LOGOS_KANA_LAYER>;
            bindings = <&logos_kana_kyu_combo>;
        };

        combo_logos_kana_kyo {
            timeout-ms = <LOGOS_KANA_COMBO_TIMEOUT_MS>;
            key-positions = <LOGOS_KANA_POS_E LOGOS_KANA_POS_I>;
            layers = <LOGOS_KANA_LAYER>;
            bindings = <&logos_kana_kyo_combo>;
        };

        combo_logos_kana_tya {
            timeout-ms = <LOGOS_KANA_COMBO_TIMEOUT_MS>;
            key-positions = <LOGOS_KANA_POS_E LOGOS_KANA_POS_N>;
            layers = <LOGOS_KANA_LAYER>;
            bindings = <&logos_kana_tya_combo>;
        };

        combo_logos_kana_tyu {
            timeout-ms = <LOGOS_KANA_COMBO_TIMEOUT_MS>;
            key-positions = <LOGOS_KANA_POS_E LOGOS_KANA_POS_Y>;
            layers = <LOGOS_KANA_LAYER>;
            bindings = <&logos_kana_tyu_combo>;
        };

        combo_logos_kana_tyo {
            timeout-ms = <LOGOS_KANA_COMBO_TIMEOUT_MS>;
            key-positions = <LOGOS_KANA_POS_E LOGOS_KANA_POS_H>;
            layers = <LOGOS_KANA_LAYER>;
            bindings = <&logos_kana_tyo_combo>;
        };

        combo_logos_kana_hya {
            timeout-ms = <LOGOS_KANA_COMBO_TIMEOUT_MS>;
            key-positions = <LOGOS_KANA_POS_E LOGOS_KANA_POS_SLASH>;
            layers = <LOGOS_KANA_LAYER>;
            bindings = <&logos_kana_hya_combo>;
        };

        combo_logos_kana_hyu {
            timeout-ms = <LOGOS_KANA_COMBO_TIMEOUT_MS>;
            key-positions = <LOGOS_KANA_POS_E LOGOS_KANA_POS_P>;
            layers = <LOGOS_KANA_LAYER>;
            bindings = <&logos_kana_hyu_combo>;
        };

        combo_logos_kana_hyo {
            timeout-ms = <LOGOS_KANA_COMBO_TIMEOUT_MS>;
            key-positions = <LOGOS_KANA_POS_E LOGOS_KANA_POS_SEMI>;
            layers = <LOGOS_KANA_LAYER>;
            bindings = <&logos_kana_hyo_combo>;
        };

        combo_logos_kana_ja {
            timeout-ms = <LOGOS_KANA_COMBO_TIMEOUT_MS>;
            key-positions = <LOGOS_KANA_POS_W LOGOS_KANA_POS_M>;
            layers = <LOGOS_KANA_LAYER>;
            bindings = <&logos_kana_ja_combo>;
        };

        combo_logos_kana_ju {
            timeout-ms = <LOGOS_KANA_COMBO_TIMEOUT_MS>;
            key-positions = <LOGOS_KANA_POS_W LOGOS_KANA_POS_U>;
            layers = <LOGOS_KANA_LAYER>;
            bindings = <&logos_kana_ju_combo>;
        };

        combo_logos_kana_jo {
            timeout-ms = <LOGOS_KANA_COMBO_TIMEOUT_MS>;
            key-positions = <LOGOS_KANA_POS_W LOGOS_KANA_POS_J>;
            layers = <LOGOS_KANA_LAYER>;
            bindings = <&logos_kana_jo_combo>;
        };

        combo_logos_kana_gya {
            timeout-ms = <LOGOS_KANA_COMBO_TIMEOUT_MS>;
            key-positions = <LOGOS_KANA_POS_W LOGOS_KANA_POS_COMMA>;
            layers = <LOGOS_KANA_LAYER>;
            bindings = <&logos_kana_gya_combo>;
        };

        combo_logos_kana_gyu {
            timeout-ms = <LOGOS_KANA_COMBO_TIMEOUT_MS>;
            key-positions = <LOGOS_KANA_POS_W LOGOS_KANA_POS_O>;
            layers = <LOGOS_KANA_LAYER>;
            bindings = <&logos_kana_gyu_combo>;
        };

        combo_logos_kana_gyo {
            timeout-ms = <LOGOS_KANA_COMBO_TIMEOUT_MS>;
            key-positions = <LOGOS_KANA_POS_W LOGOS_KANA_POS_I>;
            layers = <LOGOS_KANA_LAYER>;
            bindings = <&logos_kana_gyo_combo>;
        };

        combo_logos_kana_nya {
            timeout-ms = <LOGOS_KANA_COMBO_TIMEOUT_MS>;
            key-positions = <LOGOS_KANA_POS_W LOGOS_KANA_POS_N>;
            layers = <LOGOS_KANA_LAYER>;
            bindings = <&logos_kana_nya_combo>;
        };

        combo_logos_kana_nyu {
            timeout-ms = <LOGOS_KANA_COMBO_TIMEOUT_MS>;
            key-positions = <LOGOS_KANA_POS_W LOGOS_KANA_POS_Y>;
            layers = <LOGOS_KANA_LAYER>;
            bindings = <&logos_kana_nyu_combo>;
        };

        combo_logos_kana_nyo {
            timeout-ms = <LOGOS_KANA_COMBO_TIMEOUT_MS>;
            key-positions = <LOGOS_KANA_POS_W LOGOS_KANA_POS_H>;
            layers = <LOGOS_KANA_LAYER>;
            bindings = <&logos_kana_nyo_combo>;
        };

        combo_logos_kana_bya {
            timeout-ms = <LOGOS_KANA_COMBO_TIMEOUT_MS>;
            key-positions = <LOGOS_KANA_POS_W LOGOS_KANA_POS_SLASH>;
            layers = <LOGOS_KANA_LAYER>;
            bindings = <&logos_kana_bya_combo>;
        };

        combo_logos_kana_byu {
            timeout-ms = <LOGOS_KANA_COMBO_TIMEOUT_MS>;
            key-positions = <LOGOS_KANA_POS_W LOGOS_KANA_POS_P>;
            layers = <LOGOS_KANA_LAYER>;
            bindings = <&logos_kana_byu_combo>;
        };

        combo_logos_kana_byo {
            timeout-ms = <LOGOS_KANA_COMBO_TIMEOUT_MS>;
            key-positions = <LOGOS_KANA_POS_W LOGOS_KANA_POS_SEMI>;
            layers = <LOGOS_KANA_LAYER>;
            bindings = <&logos_kana_byo_combo>;
        };

        combo_logos_kana_rya {
            timeout-ms = <LOGOS_KANA_COMBO_TIMEOUT_MS>;
            key-positions = <LOGOS_KANA_POS_A LOGOS_KANA_POS_M>;
            layers = <LOGOS_KANA_LAYER>;
            bindings = <&logos_kana_rya_combo>;
        };

        combo_logos_kana_ryu {
            timeout-ms = <LOGOS_KANA_COMBO_TIMEOUT_MS>;
            key-positions = <LOGOS_KANA_POS_A LOGOS_KANA_POS_U>;
            layers = <LOGOS_KANA_LAYER>;
            bindings = <&logos_kana_ryu_combo>;
        };

        combo_logos_kana_ryo {
            timeout-ms = <LOGOS_KANA_COMBO_TIMEOUT_MS>;
            key-positions = <LOGOS_KANA_POS_A LOGOS_KANA_POS_J>;
            layers = <LOGOS_KANA_LAYER>;
            bindings = <&logos_kana_ryo_combo>;
        };

        combo_logos_kana_mya {
            timeout-ms = <LOGOS_KANA_COMBO_TIMEOUT_MS>;
            key-positions = <LOGOS_KANA_POS_A LOGOS_KANA_POS_COMMA>;
            layers = <LOGOS_KANA_LAYER>;
            bindings = <&logos_kana_mya_combo>;
        };

        combo_logos_kana_myu {
            timeout-ms = <LOGOS_KANA_COMBO_TIMEOUT_MS>;
            key-positions = <LOGOS_KANA_POS_A LOGOS_KANA_POS_O>;
            layers = <LOGOS_KANA_LAYER>;
            bindings = <&logos_kana_myu_combo>;
        };

        combo_logos_kana_myo {
            timeout-ms = <LOGOS_KANA_COMBO_TIMEOUT_MS>;
            key-positions = <LOGOS_KANA_POS_A LOGOS_KANA_POS_I>;
            layers = <LOGOS_KANA_LAYER>;
            bindings = <&logos_kana_myo_combo>;
        };

        combo_logos_kana_vi {
            timeout-ms = <LOGOS_KANA_COMBO_TIMEOUT_MS>;
            key-positions = <LOGOS_KANA_POS_A LOGOS_KANA_POS_N>;
            layers = <LOGOS_KANA_LAYER>;
            bindings = <&logos_kana_vi_combo>;
        };

        combo_logos_kana_va {
            timeout-ms = <LOGOS_KANA_COMBO_TIMEOUT_MS>;
            key-positions = <LOGOS_KANA_POS_A LOGOS_KANA_POS_Y>;
            layers = <LOGOS_KANA_LAYER>;
            bindings = <&logos_kana_va_combo>;
        };

        combo_logos_kana_che {
            timeout-ms = <LOGOS_KANA_COMBO_TIMEOUT_MS>;
            key-positions = <LOGOS_KANA_POS_A LOGOS_KANA_POS_H>;
            layers = <LOGOS_KANA_LAYER>;
            bindings = <&logos_kana_che_combo>;
        };

        combo_logos_kana_pya {
            timeout-ms = <LOGOS_KANA_COMBO_TIMEOUT_MS>;
            key-positions = <LOGOS_KANA_POS_A LOGOS_KANA_POS_SLASH>;
            layers = <LOGOS_KANA_LAYER>;
            bindings = <&logos_kana_pya_combo>;
        };

        combo_logos_kana_pyu {
            timeout-ms = <LOGOS_KANA_COMBO_TIMEOUT_MS>;
            key-positions = <LOGOS_KANA_POS_A LOGOS_KANA_POS_P>;
            layers = <LOGOS_KANA_LAYER>;
            bindings = <&logos_kana_pyu_combo>;
        };

        combo_logos_kana_pyo {
            timeout-ms = <LOGOS_KANA_COMBO_TIMEOUT_MS>;
            key-positions = <LOGOS_KANA_POS_A LOGOS_KANA_POS_SEMI>;
            layers = <LOGOS_KANA_LAYER>;
            bindings = <&logos_kana_pyo_combo>;
        };

        combo_logos_kana_fi {
            timeout-ms = <LOGOS_KANA_COMBO_TIMEOUT_MS>;
            key-positions = <LOGOS_KANA_POS_Z LOGOS_KANA_POS_U>;
            layers = <LOGOS_KANA_LAYER>;
            bindings = <&logos_kana_fi_combo>;
        };

        combo_logos_kana_fa {
            timeout-ms = <LOGOS_KANA_COMBO_TIMEOUT_MS>;
            key-positions = <LOGOS_KANA_POS_Z LOGOS_KANA_POS_J>;
            layers = <LOGOS_KANA_LAYER>;
            bindings = <&logos_kana_fa_combo>;
        };

        combo_logos_kana_fo {
            timeout-ms = <LOGOS_KANA_COMBO_TIMEOUT_MS>;
            key-positions = <LOGOS_KANA_POS_Z LOGOS_KANA_POS_M>;
            layers = <LOGOS_KANA_LAYER>;
            bindings = <&logos_kana_fo_combo>;
        };

        combo_logos_kana_she {
            timeout-ms = <LOGOS_KANA_COMBO_TIMEOUT_MS>;
            key-positions = <LOGOS_KANA_POS_Z LOGOS_KANA_POS_I>;
            layers = <LOGOS_KANA_LAYER>;
            bindings = <&logos_kana_she_combo>;
        };

        combo_logos_kana_je {
            timeout-ms = <LOGOS_KANA_COMBO_TIMEOUT_MS>;
            key-positions = <LOGOS_KANA_POS_Z LOGOS_KANA_POS_COMMA>;
            layers = <LOGOS_KANA_LAYER>;
            bindings = <&logos_kana_je_combo>;
        };

        combo_logos_kana_twu {
            timeout-ms = <LOGOS_KANA_COMBO_TIMEOUT_MS>;
            key-positions = <LOGOS_KANA_POS_Z LOGOS_KANA_POS_O>;
            layers = <LOGOS_KANA_LAYER>;
            bindings = <&logos_kana_twu_combo>;
        };

        combo_logos_kana_dwu {
            timeout-ms = <LOGOS_KANA_COMBO_TIMEOUT_MS>;
            key-positions = <LOGOS_KANA_POS_Z LOGOS_KANA_POS_DOT>;
            layers = <LOGOS_KANA_LAYER>;
            bindings = <&logos_kana_dwu_combo>;
        };

        combo_logos_kana_wi {
            timeout-ms = <LOGOS_KANA_COMBO_TIMEOUT_MS>;
            key-positions = <LOGOS_KANA_POS_Z LOGOS_KANA_POS_P>;
            layers = <LOGOS_KANA_LAYER>;
            bindings = <&logos_kana_wi_combo>;
        };

        combo_logos_kana_we {
            timeout-ms = <LOGOS_KANA_COMBO_TIMEOUT_MS>;
            key-positions = <LOGOS_KANA_POS_Z LOGOS_KANA_POS_SEMI>;
            layers = <LOGOS_KANA_LAYER>;
            bindings = <&logos_kana_we_combo>;
        };

        combo_logos_kana_who {
            timeout-ms = <LOGOS_KANA_COMBO_TIMEOUT_MS>;
            key-positions = <LOGOS_KANA_POS_Z LOGOS_KANA_POS_SLASH>;
            layers = <LOGOS_KANA_LAYER>;
            bindings = <&logos_kana_who_combo>;
        };

        combo_logos_kana_ve {
            timeout-ms = <LOGOS_KANA_COMBO_TIMEOUT_MS>;
            key-positions = <LOGOS_KANA_POS_Z LOGOS_KANA_POS_Y>;
            layers = <LOGOS_KANA_LAYER>;
            bindings = <&logos_kana_ve_combo>;
        };

        combo_logos_kana_fe {
            timeout-ms = <LOGOS_KANA_COMBO_TIMEOUT_MS>;
            key-positions = <LOGOS_KANA_POS_Z LOGOS_KANA_POS_H>;
            layers = <LOGOS_KANA_LAYER>;
            bindings = <&logos_kana_fe_combo>;
        };

        combo_logos_kana_vo {
            timeout-ms = <LOGOS_KANA_COMBO_TIMEOUT_MS>;
            key-positions = <LOGOS_KANA_POS_Z LOGOS_KANA_POS_N>;
            layers = <LOGOS_KANA_LAYER>;
            bindings = <&logos_kana_vo_combo>;
        };

    };
};
